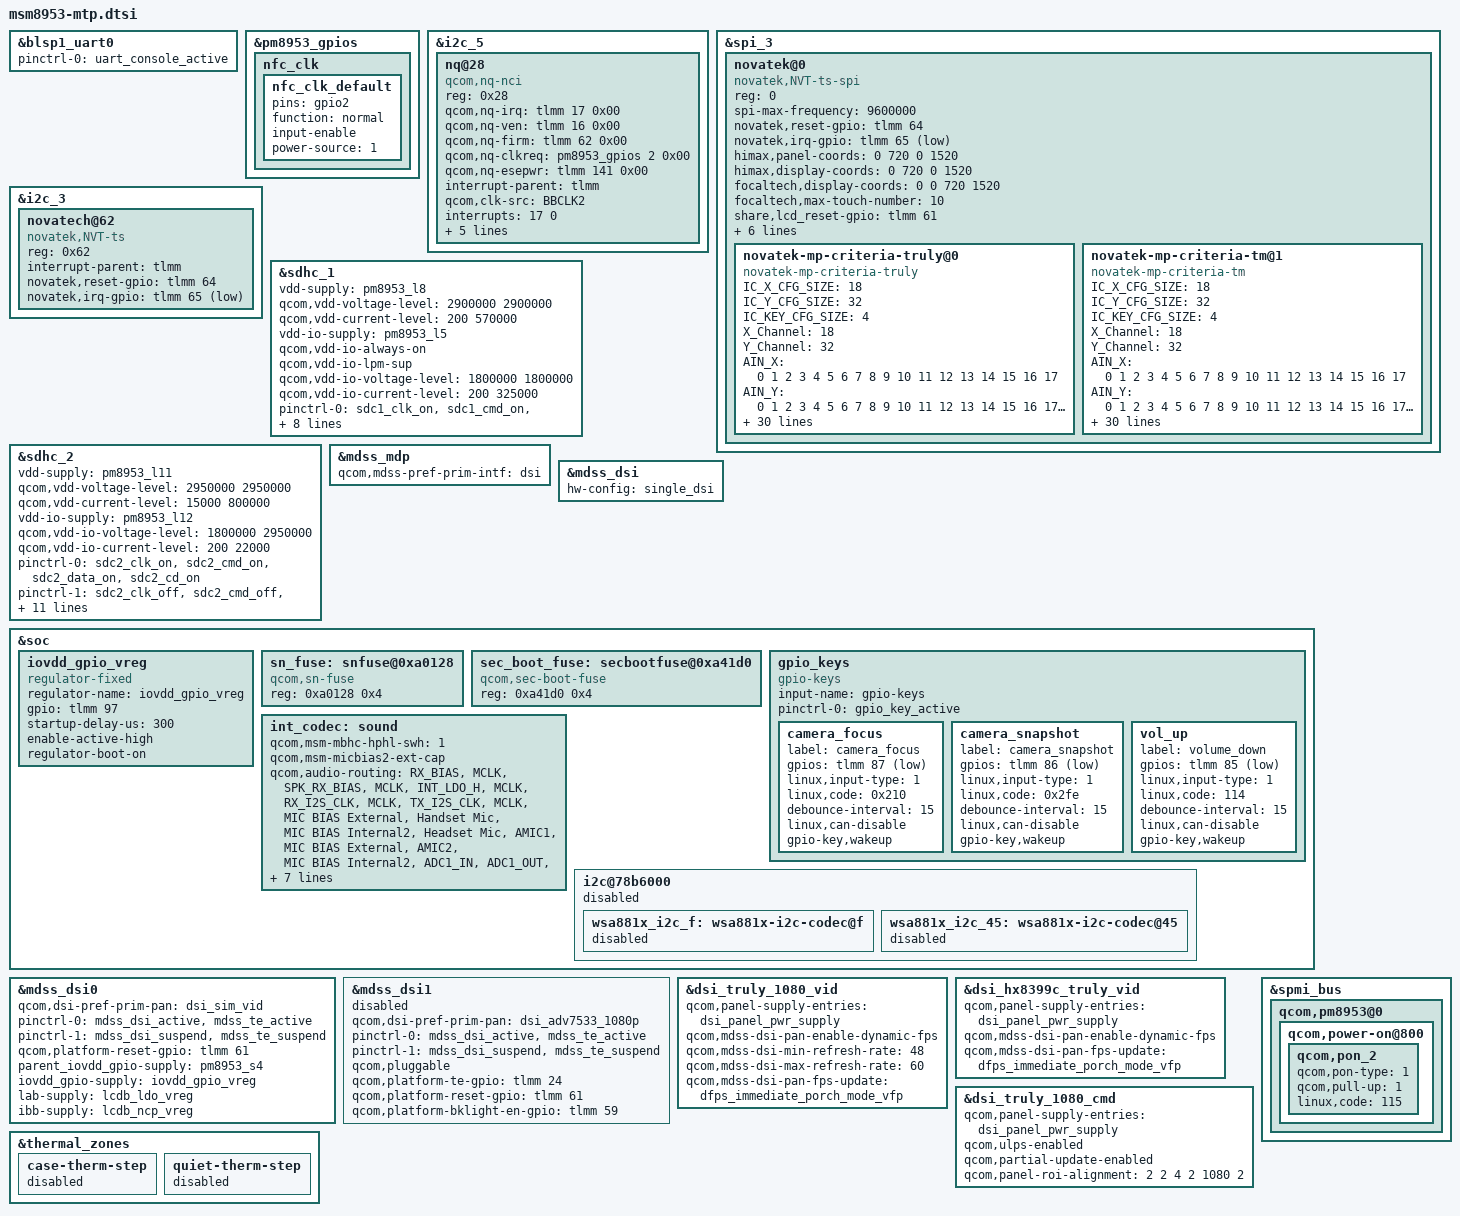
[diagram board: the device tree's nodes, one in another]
/*
 * Copyright (c) 2015-2018, The Linux Foundation. All rights reserved.
 *
 * This program is free software; you can redistribute it and/or modify
 * it under the terms of the GNU General Public License version 2 and
 * only version 2 as published by the Free Software Foundation.
 *
 * This program is distributed in the hope that it will be useful,
 * but WITHOUT ANY WARRANTY; without even the implied warranty of
 * MERCHANTABILITY or FITNESS FOR A PARTICULAR PURPOSE.  See the
 * GNU General Public License for more details.
 */

#include <dt-bindings/gpio/gpio.h>
#include <dt-bindings/clock/msm-clocks-8953.h>

//#include "msm8953-camera-sensor-mtp.dtsi"
#include "sdm450-camera-sensor-mtp-S88051AA1.dtsi"

&blsp1_uart0 {
	status = "ok";
	pinctrl-names = "default";
	pinctrl-0 = <&uart_console_active>;
};

&pm8953_gpios {
	nfc_clk {
		nfc_clk_default: nfc_clk_default {
			pins = "gpio2";
			function = "normal";
			input-enable;
			power-source = <1>;
		};
	};
};

&i2c_5 { /* BLSP2 QUP1 (NFC) */
	status = "ok";
	nq@28 {
		compatible = "qcom,nq-nci";
		reg = <0x28>;
		qcom,nq-irq = <&tlmm 17 0x00>;
		qcom,nq-ven = <&tlmm 16 0x00>;
		qcom,nq-firm = <&tlmm 62 0x00>;
		qcom,nq-clkreq = <&pm8953_gpios 2 0x00>;
		qcom,nq-esepwr = <&tlmm 141 0x00>;
		interrupt-parent = <&tlmm>;
		qcom,clk-src = "BBCLK2";
		interrupts = <17 0>;
		interrupt-names = "nfc_irq";
		pinctrl-names = "nfc_active", "nfc_suspend";
		pinctrl-0 = <&nfc_int_active &nfc_disable_active
						&nfc_clk_default>;
		pinctrl-1 = <&nfc_int_suspend &nfc_disable_suspend>;
		clocks = <&clock_gcc clk_bb_clk2_pin>;
		clock-names = "ref_clk";
	};
};

&spi_3 {
	status = "okay";
	novatek@0 {
		compatible = "novatek,NVT-ts-spi";
		reg = <0>; //Same as CS ID
		spi-max-frequency = <9600000>;	//4800000,9600000,15000000,19200000
		novatek,reset-gpio = <&tlmm 64 0x00>;
		novatek,irq-gpio = <&tlmm 65 0x2001>;
		himax,panel-coords = <0 720 0 1520>;
		himax,display-coords = <0 720 0 1520>;
		focaltech,display-coords = <0 0 720 1520>;
		focaltech,max-touch-number = <10>;
		share,lcd_reset-gpio = <&tlmm 61 0>;
		share,cs-gpio = <&tlmm 10 0>;
		lab-supply = <&lcdb_ldo_vreg>;
		ibb-supply = <&lcdb_ncp_vreg>;
		vdd-supply = <&iovdd_gpio_vreg>;
		//ctp-supply = <&pm8953_l5>;
		/* 672 */
		novatek,swrst-n8-addr = <0x01F01A>;
		novatek,mp-support-dt;
		novatek-mp-criteria-truly@0 {
			#address-cells = <1>;
			#size-cells = <0>;
			compatible = "novatek-mp-criteria-truly";
			status = "ok";
			/* MP Config */
			IC_X_CFG_SIZE = <18>;
			IC_Y_CFG_SIZE = <32>;
			IC_KEY_CFG_SIZE = <4>;
			X_Channel = <18>;
			Y_Channel = <32>;
			AIN_X = <0 1 2 3 4 5 6 7 8 9 10 11 12 13 14 15 16 17>;
			AIN_Y = <0 1 2 3 4 5 6 7 8 9 10 11 12 13 14 15 16 17 18 19
								20 21 22 23 24 25 26 27 28 29 30 31>;
			AIN_KEY = <0 1 2 0xFF>;

			/* MP Criteria */
			PS_Config_Lmt_Short_Rawdata_P = <
				14008 14008 14008 14008 14008 14008 14008 14008 14008 14008 14008 14008 14008 14008 14008 14008 14008 14008
				14008 14008 14008 14008 14008 14008 14008 14008 14008 14008 14008 14008 14008 14008 14008 14008 14008 14008
				14008 14008 14008 14008 14008 14008 14008 14008 14008 14008 14008 14008 14008 14008 14008 14008 14008 14008
				14008 14008 14008 14008 14008 14008 14008 14008 14008 14008 14008 14008 14008 14008 14008 14008 14008 14008
				14008 14008 14008 14008 14008 14008 14008 14008 14008 14008 14008 14008 14008 14008 14008 14008 14008 14008
				14008 14008 14008 14008 14008 14008 14008 14008 14008 14008 14008 14008 14008 14008 14008 14008 14008 14008
				14008 14008 14008 14008 14008 14008 14008 14008 14008 14008 14008 14008 14008 14008 14008 14008 14008 14008
				14008 14008 14008 14008 14008 14008 14008 14008 14008 14008 14008 14008 14008 14008 14008 14008 14008 14008
				14008 14008 14008 14008 14008 14008 14008 14008 14008 14008 14008 14008 14008 14008 14008 14008 14008 14008
				14008 14008 14008 14008 14008 14008 14008 14008 14008 14008 14008 14008 14008 14008 14008 14008 14008 14008
				14008 14008 14008 14008 14008 14008 14008 14008 14008 14008 14008 14008 14008 14008 14008 14008 14008 14008
				14008 14008 14008 14008 14008 14008 14008 14008 14008 14008 14008 14008 14008 14008 14008 14008 14008 14008
				14008 14008 14008 14008 14008 14008 14008 14008 14008 14008 14008 14008 14008 14008 14008 14008 14008 14008
				14008 14008 14008 14008 14008 14008 14008 14008 14008 14008 14008 14008 14008 14008 14008 14008 14008 14008
				14008 14008 14008 14008 14008 14008 14008 14008 14008 14008 14008 14008 14008 14008 14008 14008 14008 14008
				14008 14008 14008 14008 14008 14008 14008 14008 14008 14008 14008 14008 14008 14008 14008 14008 14008 14008
				14008 14008 14008 14008 14008 14008 14008 14008 14008 14008 14008 14008 14008 14008 14008 14008 14008 14008
				14008 14008 14008 14008 14008 14008 14008 14008 14008 14008 14008 14008 14008 14008 14008 14008 14008 14008
				14008 14008 14008 14008 14008 14008 14008 14008 14008 14008 14008 14008 14008 14008 14008 14008 14008 14008
				14008 14008 14008 14008 14008 14008 14008 14008 14008 14008 14008 14008 14008 14008 14008 14008 14008 14008
				14008 14008 14008 14008 14008 14008 14008 14008 14008 14008 14008 14008 14008 14008 14008 14008 14008 14008
				14008 14008 14008 14008 14008 14008 14008 14008 14008 14008 14008 14008 14008 14008 14008 14008 14008 14008
				14008 14008 14008 14008 14008 14008 14008 14008 14008 14008 14008 14008 14008 14008 14008 14008 14008 14008
				14008 14008 14008 14008 14008 14008 14008 14008 14008 14008 14008 14008 14008 14008 14008 14008 14008 14008
				14008 14008 14008 14008 14008 14008 14008 14008 14008 14008 14008 14008 14008 14008 14008 14008 14008 14008
				14008 14008 14008 14008 14008 14008 14008 14008 14008 14008 14008 14008 14008 14008 14008 14008 14008 14008
				14008 14008 14008 14008 14008 14008 14008 14008 14008 14008 14008 14008 14008 14008 14008 14008 14008 14008
				14008 14008 14008 14008 14008 14008 14008 14008 14008 14008 14008 14008 14008 14008 14008 14008 14008 14008
				14008 14008 14008 14008 14008 14008 14008 14008 14008 14008 14008 14008 14008 14008 14008 14008 14008 14008
				14008 14008 14008 14008 14008 14008 14008 14008 14008 14008 14008 14008 14008 14008 14008 14008 14008 14008
				14008 14008 14008 14008 14008 14008 14008 14008 14008 14008 14008 14008 14008 14008 14008 14008 14008 14008
				14008 14008 14008 14008 14008 14008 14008 14008 14008 14008 14008 14008 14008 14008 14008 14008 14008 14008
				>;

			PS_Config_Lmt_Short_Rawdata_N = <
				11376 11376 11376 11376 11376 11376 11376 11376 11376 11376 11376 11376 11376 11376 11376 11376 11376 11376
				11376 11376 11376 11376 11376 11376 11376 11376 11376 11376 11376 11376 11376 11376 11376 11376 11376 11376
				11376 11376 11376 11376 11376 11376 11376 11376 11376 11376 11376 11376 11376 11376 11376 11376 11376 11376
				11376 11376 11376 11376 11376 11376 11376 11376 11376 11376 11376 11376 11376 11376 11376 11376 11376 11376
				11376 11376 11376 11376 11376 11376 11376 11376 11376 11376 11376 11376 11376 11376 11376 11376 11376 11376
				11376 11376 11376 11376 11376 11376 11376 11376 11376 11376 11376 11376 11376 11376 11376 11376 11376 11376
				11376 11376 11376 11376 11376 11376 11376 11376 11376 11376 11376 11376 11376 11376 11376 11376 11376 11376
				11376 11376 11376 11376 11376 11376 11376 11376 11376 11376 11376 11376 11376 11376 11376 11376 11376 11376
				11376 11376 11376 11376 11376 11376 11376 11376 11376 11376 11376 11376 11376 11376 11376 11376 11376 11376
				11376 11376 11376 11376 11376 11376 11376 11376 11376 11376 11376 11376 11376 11376 11376 11376 11376 11376
				11376 11376 11376 11376 11376 11376 11376 11376 11376 11376 11376 11376 11376 11376 11376 11376 11376 11376
				11376 11376 11376 11376 11376 11376 11376 11376 11376 11376 11376 11376 11376 11376 11376 11376 11376 11376
				11376 11376 11376 11376 11376 11376 11376 11376 11376 11376 11376 11376 11376 11376 11376 11376 11376 11376
				11376 11376 11376 11376 11376 11376 11376 11376 11376 11376 11376 11376 11376 11376 11376 11376 11376 11376
				11376 11376 11376 11376 11376 11376 11376 11376 11376 11376 11376 11376 11376 11376 11376 11376 11376 11376
				11376 11376 11376 11376 11376 11376 11376 11376 11376 11376 11376 11376 11376 11376 11376 11376 11376 11376
				11376 11376 11376 11376 11376 11376 11376 11376 11376 11376 11376 11376 11376 11376 11376 11376 11376 11376
				11376 11376 11376 11376 11376 11376 11376 11376 11376 11376 11376 11376 11376 11376 11376 11376 11376 11376
				11376 11376 11376 11376 11376 11376 11376 11376 11376 11376 11376 11376 11376 11376 11376 11376 11376 11376
				11376 11376 11376 11376 11376 11376 11376 11376 11376 11376 11376 11376 11376 11376 11376 11376 11376 11376
				11376 11376 11376 11376 11376 11376 11376 11376 11376 11376 11376 11376 11376 11376 11376 11376 11376 11376
				11376 11376 11376 11376 11376 11376 11376 11376 11376 11376 11376 11376 11376 11376 11376 11376 11376 11376
				11376 11376 11376 11376 11376 11376 11376 11376 11376 11376 11376 11376 11376 11376 11376 11376 11376 11376
				11376 11376 11376 11376 11376 11376 11376 11376 11376 11376 11376 11376 11376 11376 11376 11376 11376 11376
				11376 11376 11376 11376 11376 11376 11376 11376 11376 11376 11376 11376 11376 11376 11376 11376 11376 11376
				11376 11376 11376 11376 11376 11376 11376 11376 11376 11376 11376 11376 11376 11376 11376 11376 11376 11376
				11376 11376 11376 11376 11376 11376 11376 11376 11376 11376 11376 11376 11376 11376 11376 11376 11376 11376
				11376 11376 11376 11376 11376 11376 11376 11376 11376 11376 11376 11376 11376 11376 11376 11376 11376 11376
				11376 11376 11376 11376 11376 11376 11376 11376 11376 11376 11376 11376 11376 11376 11376 11376 11376 11376
				11376 11376 11376 11376 11376 11376 11376 11376 11376 11376 11376 11376 11376 11376 11376 11376 11376 11376
				11376 11376 11376 11376 11376 11376 11376 11376 11376 11376 11376 11376 11376 11376 11376 11376 11376 11376
				11376 11376 11376 11376 11376 11376 11376 11376 11376 11376 11376 11376 11376 11376 11376 11376 11376 11376
				>;

			PS_Config_Lmt_Open_Rawdata_P = <
				2200	2004	1799	1603	1555	1710	65535	65535	65535	65535	65535	65535	1724	1562	1613	1811	2014	2209
				1752	1762	1753	1750	1751	1745	1745	1597	1583	1587	1600	1751	1751	1756	1759	1762	1769	1763
				1731	1735	1727	1724	1725	1718	1718	1723	1709	1710	1724	1722	1724	1728	1731	1734	1738	1740
				1718	1722	1713	1710	1711	1704	1704	1709	1695	1701	1715	1713	1714	1720	1722	1725	1730	1731
				1744	1748	1740	1736	1737	1731	1731	1735	1721	1730	1744	1742	1743	1748	1751	1754	1759	1761
				1741	1744	1735	1731	1733	1726	1726	1732	1717	1724	1739	1736	1738	1743	1746	1748	1753	1755
				1706	1709	1701	1696	1697	1691	1691	1696	1682	1689	1703	1701	1702	1707	1710	1713	1718	1721
				1705	1708	1699	1694	1696	1689	1689	1695	1680	1684	1698	1696	1697	1702	1705	1708	1713	1714
				1731	1734	1725	1721	1722	1716	1716	1721	1707	1714	1728	1726	1727	1732	1735	1738	1743	1745
				1728	1731	1722	1718	1720	1713	1713	1718	1703	1708	1723	1720	1722	1727	1730	1732	1738	1739
				1690	1692	1684	1679	1680	1674	1674	1679	1665	1670	1684	1682	1683	1688	1691	1694	1699	1701
				1686	1689	1680	1676	1678	1671	1670	1676	1661	1665	1680	1677	1678	1684	1686	1689	1695	1696
				1717	1719	1711	1706	1708	1702	1701	1706	1692	1699	1713	1710	1712	1717	1719	1723	1728	1731
				1712	1714	1705	1701	1703	1696	1696	1701	1686	1693	1708	1705	1707	1712	1714	1717	1724	1726
				1677	1678	1670	1666	1667	1661	1661	1665	1651	1656	1670	1667	1669	1674	1676	1679	1685	1688
				1672	1673	1665	1660	1662	1655	1655	1660	1645	1651	1665	1663	1664	1669	1671	1674	1681	1684
				1672	1672	1663	1660	1660	1654	1654	1658	1644	1649	1662	1660	1661	1666	1668	1672	1677	1681
				1665	1666	1657	1653	1654	1647	1647	1652	1637	1643	1657	1654	1655	1661	1662	1667	1672	1675
				1693	1693	1684	1680	1680	1674	1674	1678	1664	1671	1685	1683	1684	1689	1691	1696	1701	1705
				1686	1686	1677	1673	1674	1667	1667	1672	1657	1663	1678	1675	1677	1682	1683	1688	1694	1697
				1649	1648	1640	1636	1636	1630	1630	1634	1620	1626	1640	1638	1640	1645	1647	1652	1656	1661
				1644	1644	1635	1631	1632	1625	1625	1630	1615	1621	1636	1633	1634	1640	1641	1646	1652	1656
				1669	1670	1659	1655	1656	1649	1649	1653	1639	1647	1661	1658	1661	1666	1667	1673	1678	1683
				1665	1667	1655	1651	1652	1645	1645	1649	1635	1640	1655	1652	1654	1659	1661	1666	1674	1676
				1629	1629	1620	1615	1615	1609	1609	1613	1599	1605	1619	1617	1619	1624	1626	1631	1638	1641
				1627	1628	1619	1613	1614	1607	1607	1612	1597	1602	1617	1614	1616	1621	1623	1629	1636	1638
				1656	1655	1648	1641	1642	1635	1635	1639	1624	1628	1643	1641	1642	1648	1649	1657	1662	1666
				1652	1652	1644	1637	1638	1631	1631	1636	1620	1624	1640	1637	1639	1644	1646	1653	1659	1662
				1615	1614	1606	1599	1600	1594	1593	1598	1583	1587	1602	1600	1602	1607	1608	1616	1621	1625
				1618	1617	1609	1603	1604	1597	1596	1601	1586	1590	1605	1602	1605	1610	1612	1619	1624	1629
				1637	1635	1628	1620	1621	1614	1614	1618	1603	1608	1623	1621	1623	1628	1632	1638	1644	1649
				1297	1636	1627	1622	1620	1613	1612	1618	1602	1608	1625	1621	1624	1628	1632	1638	1645	1309
				>;

			PS_Config_Lmt_Open_Rawdata_N = <
				943	859	771	687	666	733	0	0	0	0	0	0	739	670	691	776	863	947
				751	755	751	750	750	748	748	684	679	680	686	751	750	753	754	755	758	755
				742	744	740	739	739	736	736	738	732	733	739	738	739	741	742	743	745	746
				736	738	734	733	733	730	730	732	726	729	735	734	735	737	738	739	741	742
				748	749	746	744	745	742	742	744	738	742	748	747	747	749	750	752	754	755
				746	747	744	742	743	740	740	742	736	739	745	744	745	747	748	749	751	752
				731	732	729	727	727	725	725	727	721	724	730	729	730	732	733	734	736	737
				731	732	728	726	727	724	724	726	720	722	728	727	727	730	731	732	734	735
				742	743	739	737	738	735	735	738	731	735	741	740	740	742	744	745	747	748
				741	742	738	736	737	734	734	736	730	732	738	737	738	740	741	742	745	745
				724	725	722	720	720	718	717	720	714	716	722	721	721	723	725	726	728	729
				723	724	720	718	719	716	716	718	712	714	720	719	719	722	722	724	726	727
				736	737	733	731	732	729	729	731	725	728	734	733	734	736	737	738	741	742
				734	734	731	729	730	727	727	729	723	726	732	731	731	734	735	736	739	740
				719	719	716	714	714	712	712	714	708	710	716	715	715	717	718	720	722	723
				716	717	713	712	712	709	709	711	705	708	714	713	713	715	716	717	720	722
				716	717	713	711	712	709	709	711	705	707	712	711	712	714	715	717	719	720
				713	714	710	708	709	706	706	708	702	704	710	709	709	712	712	714	717	718
				725	725	722	720	720	717	717	719	713	716	722	721	722	724	725	727	729	731
				722	723	719	717	717	714	714	717	710	713	719	718	719	721	721	724	726	727
				707	706	703	701	701	699	698	700	694	697	703	702	703	705	706	708	710	712
				705	705	701	699	699	696	696	698	692	695	701	700	700	703	703	706	708	710
				715	716	711	709	710	707	707	709	702	706	712	711	712	714	715	717	719	721
				714	714	709	708	708	705	705	707	701	703	709	708	709	711	712	714	717	718
				698	698	694	692	692	690	689	691	685	688	694	693	694	696	697	699	702	703
				697	698	694	691	692	689	689	691	684	687	693	692	692	695	696	698	701	702
				710	709	706	703	704	701	701	703	696	698	704	703	704	706	707	710	712	714
				708	708	705	701	702	699	699	701	694	696	703	702	702	705	705	708	711	712
				692	692	688	685	686	683	683	685	679	680	686	686	686	689	689	692	695	696
				694	693	690	687	687	684	684	686	680	681	688	687	688	690	691	694	696	698
				702	701	698	694	695	692	692	693	687	689	696	695	696	698	699	702	704	707
				556	701	697	695	694	691	691	693	686	689	696	695	696	698	699	702	705	561
				>;

			PS_Config_Lmt_FW_Rawdata_P = <
				824	827	832	825	838	825	65535	65535	65535	65535	65535	65535	856	841	851	843	856	855
				816	828	829	822	837	826	834	831	831	845	853	844	853	840	855	844	857	860
				818	825	839	824	832	827	834	830	834	843	855	844	853	840	853	841	855	863
				807	828	834	828	835	825	830	830	836	841	856	842	855	838	850	843	855	852
				813	823	836	828	832	829	832	831	830	843	852	843	854	839	852	841	856	860
				819	828	837	820	832	822	835	823	832	841	854	840	857	844	855	843	859	859
				815	819	825	826	836	822	834	825	832	841	855	840	854	842	855	834	840	863
				820	825	837	829	831	827	836	825	828	839	851	841	857	842	855	837	855	859
				820	827	840	827	829	828	837	830	836	841	852	843	856	841	854	840	858	862
				817	822	829	813	829	820	834	830	835	839	856	840	855	826	846	845	852	862
				816	823	836	834	831	825	833	829	833	841	861	840	851	839	861	847	856	863
				820	827	834	826	837	829	829	825	841	843	857	844	853	842	856	842	857	859
				819	828	837	831	832	813	822	830	831	846	856	832	846	846	859	839	853	862
				820	830	835	827	835	830	829	825	833	839	857	848	861	840	856	843	856	864
				812	829	834	822	839	828	830	829	829	843	855	839	855	843	857	846	858	864
				823	833	837	822	835	830	837	820	833	837	846	842	857	849	858	845	855	859
				825	828	832	828	835	830	836	826	833	845	853	841	858	844	854	841	857	860
				816	827	834	825	837	828	829	836	833	847	851	839	856	842	860	850	855	864
				835	832	835	825	836	832	835	827	832	846	859	842	850	844	856	844	853	875
				816	827	837	826	832	828	838	825	839	841	853	841	856	842	852	843	855	864
				821	829	840	830	830	826	835	828	836	845	854	847	852	840	857	847	854	861
				821	833	841	831	833	824	836	827	835	845	848	839	852	847	852	851	851	857
				822	824	832	824	835	837	838	823	843	839	850	843	856	843	850	842	853	858
				817	827	831	827	843	830	833	825	838	845	852	841	856	854	854	843	853	862
				817	823	833	829	838	832	826	827	838	848	854	842	852	850	855	842	857	863
				820	830	839	831	830	825	834	829	835	843	859	847	854	837	853	843	853	859
				818	827	832	826	832	833	846	827	836	840	853	857	856	845	855	841	859	859
				822	829	835	827	833	829	834	831	837	839	853	848	862	840	848	842	851	852
				820	825	834	826	838	829	835	824	836	845	852	843	854	840	857	845	853	858
				820	826	830	827	837	829	831	835	850	855	859	840	854	842	852	844	856	858
				820	828	835	831	831	822	837	832	836	848	854	844	854	841	851	843	851	860
				820	834	836	830	834	829	829	826	831	841	852	841	851	843	853	846	851	857
				>;

			PS_Config_Lmt_FW_Rawdata_N = <
				353	354	357	354	359	354	0	0	0	0	0	0	367	361	365	361	367	367
				350	355	355	352	359	354	358	356	356	362	365	362	365	360	367	362	367	369
				350	354	360	353	357	354	357	356	357	361	366	362	365	360	366	361	367	370
				346	355	358	355	358	353	356	356	358	360	367	361	366	359	364	361	366	365
				348	353	358	355	357	355	357	356	356	361	365	361	366	360	365	361	367	369
				351	355	359	351	357	352	358	353	357	360	366	360	367	362	366	361	368	368
				349	351	353	354	358	352	357	354	357	360	367	360	366	361	367	358	360	370
				351	354	359	355	356	355	358	354	355	360	365	361	367	361	367	359	366	368
				351	355	360	354	355	355	359	356	358	360	365	361	367	360	366	360	368	369
				350	352	355	348	355	352	358	356	358	360	367	360	366	354	362	362	365	370
				350	353	358	358	356	354	357	355	357	360	369	360	365	360	369	363	367	370
				351	354	358	354	359	355	355	353	361	361	367	362	365	361	367	361	367	368
				351	355	359	356	357	348	352	356	356	362	367	357	362	362	368	360	365	369
				351	356	358	354	358	356	355	354	357	360	367	363	369	360	367	361	367	370
				348	355	357	352	360	355	356	355	355	361	366	360	366	361	367	363	368	370
				353	357	359	352	358	356	359	351	357	359	363	361	367	364	368	362	366	368
				353	355	357	355	358	356	358	354	357	362	366	360	368	362	366	361	367	369
				350	354	357	354	359	355	355	358	357	363	365	359	367	361	369	364	367	370
				358	356	358	354	358	356	358	355	357	363	368	361	364	362	367	362	366	375
				350	355	359	354	356	355	359	353	360	360	365	360	367	361	365	361	366	370
				352	355	360	356	356	354	358	355	358	362	366	363	365	360	367	363	366	369
				352	357	360	356	357	353	358	354	358	362	363	360	365	363	365	365	365	367
				352	353	357	353	358	359	359	353	361	360	364	361	367	361	364	361	366	368
				350	354	356	355	361	356	357	354	359	362	365	360	367	366	366	361	365	369
				350	353	357	355	359	356	354	354	359	364	366	361	365	364	367	361	367	370
				351	356	360	356	356	353	357	355	358	361	368	363	366	359	366	361	366	368
				351	354	357	354	356	357	362	355	358	360	366	367	367	362	367	361	368	368
				352	355	358	354	357	355	358	356	359	360	366	363	369	360	363	361	365	365
				351	354	358	354	359	355	358	353	358	362	365	361	366	360	367	362	366	368
				352	354	356	354	359	355	356	358	364	367	368	360	366	361	365	362	367	368
				352	355	358	356	356	352	359	357	358	363	366	362	366	361	365	361	365	368
				351	357	358	356	357	355	355	354	356	360	365	360	365	361	366	362	365	367
				>;

			PS_Config_Lmt_FW_CC_P = <
				127	126	127	127	127	128	65535	65535	65535	65535	65535	65535	131	131	130	130	129	130
				130	129	129	129	130	130	130	129	130	134	133	135	134	134	133	134	133	134
				129	128	128	129	129	129	130	130	132	135	132	133	132	132	132	132	131	132
				130	129	129	129	130	130	130	131	132	136	134	134	134	134	133	133	132	133
				130	129	129	130	130	131	131	131	133	137	135	135	134	134	133	134	133	134
				130	129	129	130	130	131	131	131	133	138	136	136	135	135	134	134	133	134
				130	129	129	130	130	131	131	131	133	137	135	135	134	134	133	133	132	133
				130	129	129	130	130	131	131	131	133	137	135	135	134	134	133	133	133	134
				130	129	130	130	130	131	131	131	133	137	135	135	134	134	134	134	133	134
				130	129	130	130	130	131	131	131	133	138	136	136	135	135	134	134	134	135
				131	130	130	130	131	131	131	132	133	136	134	134	134	134	133	133	133	134
				131	130	130	130	131	131	131	131	133	137	135	135	134	134	133	133	133	134
				131	130	130	131	131	131	131	132	134	138	136	136	135	135	134	134	134	135
				131	130	130	130	131	131	131	132	134	138	136	136	135	135	134	135	134	135
				131	130	130	130	131	131	132	132	134	137	135	135	134	134	133	133	132	134
				131	129	130	130	131	131	131	132	133	137	135	135	134	134	133	133	133	134
				131	130	130	130	131	131	131	132	134	138	135	135	134	135	134	134	133	134
				131	129	129	130	130	130	131	131	133	138	136	135	134	135	134	134	133	134
				132	130	131	131	131	132	132	132	134	138	135	135	134	135	134	134	133	134
				132	130	130	131	131	131	132	132	134	137	135	135	134	134	133	133	133	134
				131	129	130	130	130	130	131	131	133	136	134	134	134	134	133	133	132	133
				131	129	129	129	130	130	130	131	133	136	134	134	133	134	133	133	133	134
				132	130	131	131	131	131	131	132	134	137	134	134	133	134	133	133	133	134
				132	131	131	131	131	131	132	132	134	136	134	134	133	134	133	133	133	134
				131	130	130	130	130	131	131	131	133	136	134	134	133	133	133	133	132	134
				131	129	129	129	130	130	131	131	133	136	134	134	133	134	133	133	133	134
				132	130	130	131	131	131	132	132	134	136	134	134	133	133	132	133	132	134
				132	130	130	130	131	131	131	132	133	136	134	134	133	133	132	132	132	133
				131	129	129	129	130	130	130	131	132	135	133	134	133	133	132	132	132	133
				130	128	128	128	129	129	129	130	131	134	132	132	131	131	130	130	130	132
				132	130	130	130	131	131	131	131	133	135	133	133	132	132	131	131	131	133
				125	130	129	129	130	130	130	131	133	135	132	132	131	131	130	131	131	125
				>;

			PS_Config_Lmt_FW_CC_N = <
				76	75	76	76	76	77	0	0	0	0	0	0	78	78	78	78	77	78
				78	77	77	78	78	78	78	77	78	81	80	81	80	81	80	80	80	80
				77	77	77	77	78	78	78	78	79	81	79	80	79	79	79	79	79	79
				78	77	77	78	78	78	78	78	79	82	81	81	80	80	80	80	79	80
				78	77	78	78	78	78	79	79	80	82	81	81	81	81	80	80	80	80
				78	77	77	78	78	78	78	79	80	83	81	81	81	81	80	80	80	81
				78	77	78	78	78	79	79	79	80	82	81	81	80	80	80	80	79	80
				78	78	78	78	78	78	79	79	80	82	81	81	80	81	80	80	80	80
				78	78	78	78	78	78	79	79	80	82	81	81	81	81	80	80	80	80
				78	78	78	78	78	78	78	79	80	83	81	81	81	81	80	81	80	81
				79	78	78	78	78	79	79	79	80	82	80	81	80	80	80	80	80	80
				78	78	78	78	78	78	79	79	80	82	81	81	80	80	80	80	80	80
				79	78	78	78	79	79	79	79	80	83	81	81	81	81	80	81	80	81
				79	78	78	78	78	79	79	79	80	83	82	82	81	81	81	81	80	81
				79	78	78	78	78	79	79	79	80	82	81	81	80	80	80	80	79	80
				78	78	78	78	78	78	79	79	80	82	81	81	80	81	80	80	80	80
				79	78	78	78	78	79	79	79	80	83	81	81	81	81	80	80	80	80
				78	78	78	78	78	78	78	79	80	83	81	81	81	81	80	80	80	81
				79	78	78	79	79	79	79	79	81	83	81	81	81	81	80	80	80	80
				79	78	78	78	79	79	79	79	80	82	81	81	80	81	80	80	80	80
				79	78	78	78	78	78	78	79	80	82	81	81	80	80	80	80	79	80
				78	78	78	78	78	78	78	79	80	82	81	81	80	80	80	80	80	80
				79	78	78	78	79	79	79	79	80	82	81	81	80	80	80	80	80	80
				79	78	78	78	79	79	79	79	80	82	81	80	80	80	80	80	80	80
				79	78	78	78	78	78	79	79	80	82	80	81	80	80	80	80	79	80
				79	78	78	78	78	78	78	79	80	82	81	80	80	80	80	80	80	80
				79	78	78	78	79	79	79	79	80	82	80	80	80	80	79	80	79	80
				79	78	78	78	78	79	79	79	80	82	80	80	80	80	79	79	79	80
				79	78	78	78	78	78	78	78	79	81	80	80	80	80	79	79	79	80
				78	77	77	77	77	77	77	78	79	80	79	79	79	79	78	78	78	79
				79	78	78	78	78	78	79	79	80	81	80	80	79	79	79	79	79	80
				75	78	78	78	78	78	78	78	80	81	79	79	79	79	78	79	79	75
				>;

			PS_Config_Lmt_FW_Diff_P = <
				50 50 50 50 50 50 65535 65535 65535 65535 65535 65535 50 50 50 50 50 50
				50 50 50 50 50 50    50    50    50    50    50    50 50 50 50 50 50 50
				50 50 50 50 50 50    50    50    50    50    50    50 50 50 50 50 50 50
				50 50 50 50 50 50    50    50    50    50    50    50 50 50 50 50 50 50
				50 50 50 50 50 50    50    50    50    50    50    50 50 50 50 50 50 50
				50 50 50 50 50 50    50    50    50    50    50    50 50 50 50 50 50 50
				50 50 50 50 50 50    50    50    50    50    50    50 50 50 50 50 50 50
				50 50 50 50 50 50    50    50    50    50    50    50 50 50 50 50 50 50
				50 50 50 50 50 50    50    50    50    50    50    50 50 50 50 50 50 50
				50 50 50 50 50 50    50    50    50    50    50    50 50 50 50 50 50 50
				50 50 50 50 50 50    50    50    50    50    50    50 50 50 50 50 50 50
				50 50 50 50 50 50    50    50    50    50    50    50 50 50 50 50 50 50
				50 50 50 50 50 50    50    50    50    50    50    50 50 50 50 50 50 50
				50 50 50 50 50 50    50    50    50    50    50    50 50 50 50 50 50 50
				50 50 50 50 50 50    50    50    50    50    50    50 50 50 50 50 50 50
				50 50 50 50 50 50    50    50    50    50    50    50 50 50 50 50 50 50
				50 50 50 50 50 50    50    50    50    50    50    50 50 50 50 50 50 50
				50 50 50 50 50 50    50    50    50    50    50    50 50 50 50 50 50 50
				50 50 50 50 50 50    50    50    50    50    50    50 50 50 50 50 50 50
				50 50 50 50 50 50    50    50    50    50    50    50 50 50 50 50 50 50
				50 50 50 50 50 50    50    50    50    50    50    50 50 50 50 50 50 50
				50 50 50 50 50 50    50    50    50    50    50    50 50 50 50 50 50 50
				50 50 50 50 50 50    50    50    50    50    50    50 50 50 50 50 50 50
				50 50 50 50 50 50    50    50    50    50    50    50 50 50 50 50 50 50
				50 50 50 50 50 50    50    50    50    50    50    50 50 50 50 50 50 50
				50 50 50 50 50 50    50    50    50    50    50    50 50 50 50 50 50 50
				50 50 50 50 50 50    50    50    50    50    50    50 50 50 50 50 50 50
				50 50 50 50 50 50    50    50    50    50    50    50 50 50 50 50 50 50
				50 50 50 50 50 50    50    50    50    50    50    50 50 50 50 50 50 50
				50 50 50 50 50 50    50    50    50    50    50    50 50 50 50 50 50 50
				50 50 50 50 50 50    50    50    50    50    50    50 50 50 50 50 50 50
				50 50 50 50 50 50    50    50    50    50    50    50 50 50 50 50 50 50
				>;

			PS_Config_Lmt_FW_Diff_N = <
				(-50) (-50) (-50) (-50) (-50) (-50) (-65535) (-65535) (-65535) (-65535) (-65535) (-65535) (-50) (-50) (-50) (-50) (-50) (-50)
				(-50) (-50) (-50) (-50) (-50) (-50)    (-50)    (-50)    (-50)    (-50)    (-50)    (-50) (-50) (-50) (-50) (-50) (-50) (-50)
				(-50) (-50) (-50) (-50) (-50) (-50)    (-50)    (-50)    (-50)    (-50)    (-50)    (-50) (-50) (-50) (-50) (-50) (-50) (-50)
				(-50) (-50) (-50) (-50) (-50) (-50)    (-50)    (-50)    (-50)    (-50)    (-50)    (-50) (-50) (-50) (-50) (-50) (-50) (-50)
				(-50) (-50) (-50) (-50) (-50) (-50)    (-50)    (-50)    (-50)    (-50)    (-50)    (-50) (-50) (-50) (-50) (-50) (-50) (-50)
				(-50) (-50) (-50) (-50) (-50) (-50)    (-50)    (-50)    (-50)    (-50)    (-50)    (-50) (-50) (-50) (-50) (-50) (-50) (-50)
				(-50) (-50) (-50) (-50) (-50) (-50)    (-50)    (-50)    (-50)    (-50)    (-50)    (-50) (-50) (-50) (-50) (-50) (-50) (-50)
				(-50) (-50) (-50) (-50) (-50) (-50)    (-50)    (-50)    (-50)    (-50)    (-50)    (-50) (-50) (-50) (-50) (-50) (-50) (-50)
				(-50) (-50) (-50) (-50) (-50) (-50)    (-50)    (-50)    (-50)    (-50)    (-50)    (-50) (-50) (-50) (-50) (-50) (-50) (-50)
				(-50) (-50) (-50) (-50) (-50) (-50)    (-50)    (-50)    (-50)    (-50)    (-50)    (-50) (-50) (-50) (-50) (-50) (-50) (-50)
				(-50) (-50) (-50) (-50) (-50) (-50)    (-50)    (-50)    (-50)    (-50)    (-50)    (-50) (-50) (-50) (-50) (-50) (-50) (-50)
				(-50) (-50) (-50) (-50) (-50) (-50)    (-50)    (-50)    (-50)    (-50)    (-50)    (-50) (-50) (-50) (-50) (-50) (-50) (-50)
				(-50) (-50) (-50) (-50) (-50) (-50)    (-50)    (-50)    (-50)    (-50)    (-50)    (-50) (-50) (-50) (-50) (-50) (-50) (-50)
				(-50) (-50) (-50) (-50) (-50) (-50)    (-50)    (-50)    (-50)    (-50)    (-50)    (-50) (-50) (-50) (-50) (-50) (-50) (-50)
				(-50) (-50) (-50) (-50) (-50) (-50)    (-50)    (-50)    (-50)    (-50)    (-50)    (-50) (-50) (-50) (-50) (-50) (-50) (-50)
				(-50) (-50) (-50) (-50) (-50) (-50)    (-50)    (-50)    (-50)    (-50)    (-50)    (-50) (-50) (-50) (-50) (-50) (-50) (-50)
				(-50) (-50) (-50) (-50) (-50) (-50)    (-50)    (-50)    (-50)    (-50)    (-50)    (-50) (-50) (-50) (-50) (-50) (-50) (-50)
				(-50) (-50) (-50) (-50) (-50) (-50)    (-50)    (-50)    (-50)    (-50)    (-50)    (-50) (-50) (-50) (-50) (-50) (-50) (-50)
				(-50) (-50) (-50) (-50) (-50) (-50)    (-50)    (-50)    (-50)    (-50)    (-50)    (-50) (-50) (-50) (-50) (-50) (-50) (-50)
				(-50) (-50) (-50) (-50) (-50) (-50)    (-50)    (-50)    (-50)    (-50)    (-50)    (-50) (-50) (-50) (-50) (-50) (-50) (-50)
				(-50) (-50) (-50) (-50) (-50) (-50)    (-50)    (-50)    (-50)    (-50)    (-50)    (-50) (-50) (-50) (-50) (-50) (-50) (-50)
				(-50) (-50) (-50) (-50) (-50) (-50)    (-50)    (-50)    (-50)    (-50)    (-50)    (-50) (-50) (-50) (-50) (-50) (-50) (-50)
				(-50) (-50) (-50) (-50) (-50) (-50)    (-50)    (-50)    (-50)    (-50)    (-50)    (-50) (-50) (-50) (-50) (-50) (-50) (-50)
				(-50) (-50) (-50) (-50) (-50) (-50)    (-50)    (-50)    (-50)    (-50)    (-50)    (-50) (-50) (-50) (-50) (-50) (-50) (-50)
				(-50) (-50) (-50) (-50) (-50) (-50)    (-50)    (-50)    (-50)    (-50)    (-50)    (-50) (-50) (-50) (-50) (-50) (-50) (-50)
				(-50) (-50) (-50) (-50) (-50) (-50)    (-50)    (-50)    (-50)    (-50)    (-50)    (-50) (-50) (-50) (-50) (-50) (-50) (-50)
				(-50) (-50) (-50) (-50) (-50) (-50)    (-50)    (-50)    (-50)    (-50)    (-50)    (-50) (-50) (-50) (-50) (-50) (-50) (-50)
				(-50) (-50) (-50) (-50) (-50) (-50)    (-50)    (-50)    (-50)    (-50)    (-50)    (-50) (-50) (-50) (-50) (-50) (-50) (-50)
				(-50) (-50) (-50) (-50) (-50) (-50)    (-50)    (-50)    (-50)    (-50)    (-50)    (-50) (-50) (-50) (-50) (-50) (-50) (-50)
				(-50) (-50) (-50) (-50) (-50) (-50)    (-50)    (-50)    (-50)    (-50)    (-50)    (-50) (-50) (-50) (-50) (-50) (-50) (-50)
				(-50) (-50) (-50) (-50) (-50) (-50)    (-50)    (-50)    (-50)    (-50)    (-50)    (-50) (-50) (-50) (-50) (-50) (-50) (-50)
				(-50) (-50) (-50) (-50) (-50) (-50)    (-50)    (-50)    (-50)    (-50)    (-50)    (-50) (-50) (-50) (-50) (-50) (-50) (-50)
				>;

			PS_Config_Diff_Test_Frame = <50>;

			PS_Config_Lmt_LPWG_Rawdata_P = <
				800 800 800 800 800 800 65535 65535 65535 65535 65535 65535 800 800 800 800 800 800
				800 800 800 800 800 800   800   800   800   800   800   800 800 800 800 800 800 800
				800 800 800 800 800 800   800   800   800   800   800   800 800 800 800 800 800 800
				800 800 800 800 800 800   800   800   800   800   800   800 800 800 800 800 800 800
				800 800 800 800 800 800   800   800   800   800   800   800 800 800 800 800 800 800
				800 800 800 800 800 800   800   800   800   800   800   800 800 800 800 800 800 800
				800 800 800 800 800 800   800   800   800   800   800   800 800 800 800 800 800 800
				800 800 800 800 800 800   800   800   800   800   800   800 800 800 800 800 800 800
				800 800 800 800 800 800   800   800   800   800   800   800 800 800 800 800 800 800
				800 800 800 800 800 800   800   800   800   800   800   800 800 800 800 800 800 800
				800 800 800 800 800 800   800   800   800   800   800   800 800 800 800 800 800 800
				800 800 800 800 800 800   800   800   800   800   800   800 800 800 800 800 800 800
				800 800 800 800 800 800   800   800   800   800   800   800 800 800 800 800 800 800
				800 800 800 800 800 800   800   800   800   800   800   800 800 800 800 800 800 800
				800 800 800 800 800 800   800   800   800   800   800   800 800 800 800 800 800 800
				800 800 800 800 800 800   800   800   800   800   800   800 800 800 800 800 800 800
				800 800 800 800 800 800   800   800   800   800   800   800 800 800 800 800 800 800
				800 800 800 800 800 800   800   800   800   800   800   800 800 800 800 800 800 800
				800 800 800 800 800 800   800   800   800   800   800   800 800 800 800 800 800 800
				800 800 800 800 800 800   800   800   800   800   800   800 800 800 800 800 800 800
				800 800 800 800 800 800   800   800   800   800   800   800 800 800 800 800 800 800
				800 800 800 800 800 800   800   800   800   800   800   800 800 800 800 800 800 800
				800 800 800 800 800 800   800   800   800   800   800   800 800 800 800 800 800 800
				800 800 800 800 800 800   800   800   800   800   800   800 800 800 800 800 800 800
				800 800 800 800 800 800   800   800   800   800   800   800 800 800 800 800 800 800
				800 800 800 800 800 800   800   800   800   800   800   800 800 800 800 800 800 800
				800 800 800 800 800 800   800   800   800   800   800   800 800 800 800 800 800 800
				800 800 800 800 800 800   800   800   800   800   800   800 800 800 800 800 800 800
				800 800 800 800 800 800   800   800   800   800   800   800 800 800 800 800 800 800
				800 800 800 800 800 800   800   800   800   800   800   800 800 800 800 800 800 800
				800 800 800 800 800 800   800   800   800   800   800   800 800 800 800 800 800 800
				800 800 800 800 800 800   800   800   800   800   800   800 800 800 800 800 800 800
				>;

			PS_Config_Lmt_LPWG_Rawdata_N = <
				400 400 400 400 400 400   0   0   0   0   0   0 400 400 400 400 400 400
				400 400 400 400 400 400 400 400 400 400 400 400 400 400 400 400 400 400
				400 400 400 400 400 400 400 400 400 400 400 400 400 400 400 400 400 400
				400 400 400 400 400 400 400 400 400 400 400 400 400 400 400 400 400 400
				400 400 400 400 400 400 400 400 400 400 400 400 400 400 400 400 400 400
				400 400 400 400 400 400 400 400 400 400 400 400 400 400 400 400 400 400
				400 400 400 400 400 400 400 400 400 400 400 400 400 400 400 400 400 400
				400 400 400 400 400 400 400 400 400 400 400 400 400 400 400 400 400 400
				400 400 400 400 400 400 400 400 400 400 400 400 400 400 400 400 400 400
				400 400 400 400 400 400 400 400 400 400 400 400 400 400 400 400 400 400
				400 400 400 400 400 400 400 400 400 400 400 400 400 400 400 400 400 400
				400 400 400 400 400 400 400 400 400 400 400 400 400 400 400 400 400 400
				400 400 400 400 400 400 400 400 400 400 400 400 400 400 400 400 400 400
				400 400 400 400 400 400 400 400 400 400 400 400 400 400 400 400 400 400
				400 400 400 400 400 400 400 400 400 400 400 400 400 400 400 400 400 400
				400 400 400 400 400 400 400 400 400 400 400 400 400 400 400 400 400 400
				400 400 400 400 400 400 400 400 400 400 400 400 400 400 400 400 400 400
				400 400 400 400 400 400 400 400 400 400 400 400 400 400 400 400 400 400
				400 400 400 400 400 400 400 400 400 400 400 400 400 400 400 400 400 400
				400 400 400 400 400 400 400 400 400 400 400 400 400 400 400 400 400 400
				400 400 400 400 400 400 400 400 400 400 400 400 400 400 400 400 400 400
				400 400 400 400 400 400 400 400 400 400 400 400 400 400 400 400 400 400
				400 400 400 400 400 400 400 400 400 400 400 400 400 400 400 400 400 400
				400 400 400 400 400 400 400 400 400 400 400 400 400 400 400 400 400 400
				400 400 400 400 400 400 400 400 400 400 400 400 400 400 400 400 400 400
				400 400 400 400 400 400 400 400 400 400 400 400 400 400 400 400 400 400
				400 400 400 400 400 400 400 400 400 400 400 400 400 400 400 400 400 400
				400 400 400 400 400 400 400 400 400 400 400 400 400 400 400 400 400 400
				400 400 400 400 400 400 400 400 400 400 400 400 400 400 400 400 400 400
				400 400 400 400 400 400 400 400 400 400 400 400 400 400 400 400 400 400
				400 400 400 400 400 400 400 400 400 400 400 400 400 400 400 400 400 400
				400 400 400 400 400 400 400 400 400 400 400 400 400 400 400 400 400 400
				>;

			PS_Config_Lmt_LPWG_Diff_P = <
				50 50 50 50 50 50 65535 65535 65535 65535 65535 65535 50 50 50 50 50 50
				50 50 50 50 50 50    50    50    50    50    50    50 50 50 50 50 50 50
				50 50 50 50 50 50    50    50    50    50    50    50 50 50 50 50 50 50
				50 50 50 50 50 50    50    50    50    50    50    50 50 50 50 50 50 50
				50 50 50 50 50 50    50    50    50    50    50    50 50 50 50 50 50 50
				50 50 50 50 50 50    50    50    50    50    50    50 50 50 50 50 50 50
				50 50 50 50 50 50    50    50    50    50    50    50 50 50 50 50 50 50
				50 50 50 50 50 50    50    50    50    50    50    50 50 50 50 50 50 50
				50 50 50 50 50 50    50    50    50    50    50    50 50 50 50 50 50 50
				50 50 50 50 50 50    50    50    50    50    50    50 50 50 50 50 50 50
				50 50 50 50 50 50    50    50    50    50    50    50 50 50 50 50 50 50
				50 50 50 50 50 50    50    50    50    50    50    50 50 50 50 50 50 50
				50 50 50 50 50 50    50    50    50    50    50    50 50 50 50 50 50 50
				50 50 50 50 50 50    50    50    50    50    50    50 50 50 50 50 50 50
				50 50 50 50 50 50    50    50    50    50    50    50 50 50 50 50 50 50
				50 50 50 50 50 50    50    50    50    50    50    50 50 50 50 50 50 50
				50 50 50 50 50 50    50    50    50    50    50    50 50 50 50 50 50 50
				50 50 50 50 50 50    50    50    50    50    50    50 50 50 50 50 50 50
				50 50 50 50 50 50    50    50    50    50    50    50 50 50 50 50 50 50
				50 50 50 50 50 50    50    50    50    50    50    50 50 50 50 50 50 50
				50 50 50 50 50 50    50    50    50    50    50    50 50 50 50 50 50 50
				50 50 50 50 50 50    50    50    50    50    50    50 50 50 50 50 50 50
				50 50 50 50 50 50    50    50    50    50    50    50 50 50 50 50 50 50
				50 50 50 50 50 50    50    50    50    50    50    50 50 50 50 50 50 50
				50 50 50 50 50 50    50    50    50    50    50    50 50 50 50 50 50 50
				50 50 50 50 50 50    50    50    50    50    50    50 50 50 50 50 50 50
				50 50 50 50 50 50    50    50    50    50    50    50 50 50 50 50 50 50
				50 50 50 50 50 50    50    50    50    50    50    50 50 50 50 50 50 50
				50 50 50 50 50 50    50    50    50    50    50    50 50 50 50 50 50 50
				50 50 50 50 50 50    50    50    50    50    50    50 50 50 50 50 50 50
				50 50 50 50 50 50    50    50    50    50    50    50 50 50 50 50 50 50
				50 50 50 50 50 50    50    50    50    50    50    50 50 50 50 50 50 50
				>;

			PS_Config_Lmt_LPWG_Diff_N = <
				(-50) (-50) (-50) (-50) (-50) (-50) (-65535) (-65535) (-65535) (-65535) (-65535) (-65535) (-50) (-50) (-50) (-50) (-50) (-50)
				(-50) (-50) (-50) (-50) (-50) (-50)    (-50)    (-50)    (-50)    (-50)    (-50)    (-50) (-50) (-50) (-50) (-50) (-50) (-50)
				(-50) (-50) (-50) (-50) (-50) (-50)    (-50)    (-50)    (-50)    (-50)    (-50)    (-50) (-50) (-50) (-50) (-50) (-50) (-50)
				(-50) (-50) (-50) (-50) (-50) (-50)    (-50)    (-50)    (-50)    (-50)    (-50)    (-50) (-50) (-50) (-50) (-50) (-50) (-50)
				(-50) (-50) (-50) (-50) (-50) (-50)    (-50)    (-50)    (-50)    (-50)    (-50)    (-50) (-50) (-50) (-50) (-50) (-50) (-50)
				(-50) (-50) (-50) (-50) (-50) (-50)    (-50)    (-50)    (-50)    (-50)    (-50)    (-50) (-50) (-50) (-50) (-50) (-50) (-50)
				(-50) (-50) (-50) (-50) (-50) (-50)    (-50)    (-50)    (-50)    (-50)    (-50)    (-50) (-50) (-50) (-50) (-50) (-50) (-50)
				(-50) (-50) (-50) (-50) (-50) (-50)    (-50)    (-50)    (-50)    (-50)    (-50)    (-50) (-50) (-50) (-50) (-50) (-50) (-50)
				(-50) (-50) (-50) (-50) (-50) (-50)    (-50)    (-50)    (-50)    (-50)    (-50)    (-50) (-50) (-50) (-50) (-50) (-50) (-50)
				(-50) (-50) (-50) (-50) (-50) (-50)    (-50)    (-50)    (-50)    (-50)    (-50)    (-50) (-50) (-50) (-50) (-50) (-50) (-50)
				(-50) (-50) (-50) (-50) (-50) (-50)    (-50)    (-50)    (-50)    (-50)    (-50)    (-50) (-50) (-50) (-50) (-50) (-50) (-50)
				(-50) (-50) (-50) (-50) (-50) (-50)    (-50)    (-50)    (-50)    (-50)    (-50)    (-50) (-50) (-50) (-50) (-50) (-50) (-50)
				(-50) (-50) (-50) (-50) (-50) (-50)    (-50)    (-50)    (-50)    (-50)    (-50)    (-50) (-50) (-50) (-50) (-50) (-50) (-50)
				(-50) (-50) (-50) (-50) (-50) (-50)    (-50)    (-50)    (-50)    (-50)    (-50)    (-50) (-50) (-50) (-50) (-50) (-50) (-50)
				(-50) (-50) (-50) (-50) (-50) (-50)    (-50)    (-50)    (-50)    (-50)    (-50)    (-50) (-50) (-50) (-50) (-50) (-50) (-50)
				(-50) (-50) (-50) (-50) (-50) (-50)    (-50)    (-50)    (-50)    (-50)    (-50)    (-50) (-50) (-50) (-50) (-50) (-50) (-50)
				(-50) (-50) (-50) (-50) (-50) (-50)    (-50)    (-50)    (-50)    (-50)    (-50)    (-50) (-50) (-50) (-50) (-50) (-50) (-50)
				(-50) (-50) (-50) (-50) (-50) (-50)    (-50)    (-50)    (-50)    (-50)    (-50)    (-50) (-50) (-50) (-50) (-50) (-50) (-50)
				(-50) (-50) (-50) (-50) (-50) (-50)    (-50)    (-50)    (-50)    (-50)    (-50)    (-50) (-50) (-50) (-50) (-50) (-50) (-50)
				(-50) (-50) (-50) (-50) (-50) (-50)    (-50)    (-50)    (-50)    (-50)    (-50)    (-50) (-50) (-50) (-50) (-50) (-50) (-50)
				(-50) (-50) (-50) (-50) (-50) (-50)    (-50)    (-50)    (-50)    (-50)    (-50)    (-50) (-50) (-50) (-50) (-50) (-50) (-50)
				(-50) (-50) (-50) (-50) (-50) (-50)    (-50)    (-50)    (-50)    (-50)    (-50)    (-50) (-50) (-50) (-50) (-50) (-50) (-50)
				(-50) (-50) (-50) (-50) (-50) (-50)    (-50)    (-50)    (-50)    (-50)    (-50)    (-50) (-50) (-50) (-50) (-50) (-50) (-50)
				(-50) (-50) (-50) (-50) (-50) (-50)    (-50)    (-50)    (-50)    (-50)    (-50)    (-50) (-50) (-50) (-50) (-50) (-50) (-50)
				(-50) (-50) (-50) (-50) (-50) (-50)    (-50)    (-50)    (-50)    (-50)    (-50)    (-50) (-50) (-50) (-50) (-50) (-50) (-50)
				(-50) (-50) (-50) (-50) (-50) (-50)    (-50)    (-50)    (-50)    (-50)    (-50)    (-50) (-50) (-50) (-50) (-50) (-50) (-50)
				(-50) (-50) (-50) (-50) (-50) (-50)    (-50)    (-50)    (-50)    (-50)    (-50)    (-50) (-50) (-50) (-50) (-50) (-50) (-50)
				(-50) (-50) (-50) (-50) (-50) (-50)    (-50)    (-50)    (-50)    (-50)    (-50)    (-50) (-50) (-50) (-50) (-50) (-50) (-50)
				(-50) (-50) (-50) (-50) (-50) (-50)    (-50)    (-50)    (-50)    (-50)    (-50)    (-50) (-50) (-50) (-50) (-50) (-50) (-50)
				(-50) (-50) (-50) (-50) (-50) (-50)    (-50)    (-50)    (-50)    (-50)    (-50)    (-50) (-50) (-50) (-50) (-50) (-50) (-50)
				(-50) (-50) (-50) (-50) (-50) (-50)    (-50)    (-50)    (-50)    (-50)    (-50)    (-50) (-50) (-50) (-50) (-50) (-50) (-50)
				(-50) (-50) (-50) (-50) (-50) (-50)    (-50)    (-50)    (-50)    (-50)    (-50)    (-50) (-50) (-50) (-50) (-50) (-50) (-50)
				>;
		};

		novatek-mp-criteria-tm@1 {
			#address-cells = <1>;
			#size-cells = <0>;
			compatible = "novatek-mp-criteria-tm";
			status = "ok";
			/* MP Config */
			IC_X_CFG_SIZE = <18>;
			IC_Y_CFG_SIZE = <32>;
			IC_KEY_CFG_SIZE = <4>;
			X_Channel = <18>;
			Y_Channel = <32>;
			AIN_X = <0 1 2 3 4 5 6 7 8 9 10 11 12 13 14 15 16 17>;
			AIN_Y = <0 1 2 3 4 5 6 7 8 9 10 11 12 13 14 15 16 17 18 19
								20 21 22 23 24 25 26 27 28 29 30 31>;
			AIN_KEY = <0 1 2 0xFF>;

			/* MP Criteria */
			PS_Config_Lmt_Short_Rawdata_P = <
				14008 14008 14008 14008 14008 14008 14008 14008 14008 14008 14008 14008 14008 14008 14008 14008 14008 14008
				14008 14008 14008 14008 14008 14008 14008 14008 14008 14008 14008 14008 14008 14008 14008 14008 14008 14008
				14008 14008 14008 14008 14008 14008 14008 14008 14008 14008 14008 14008 14008 14008 14008 14008 14008 14008
				14008 14008 14008 14008 14008 14008 14008 14008 14008 14008 14008 14008 14008 14008 14008 14008 14008 14008
				14008 14008 14008 14008 14008 14008 14008 14008 14008 14008 14008 14008 14008 14008 14008 14008 14008 14008
				14008 14008 14008 14008 14008 14008 14008 14008 14008 14008 14008 14008 14008 14008 14008 14008 14008 14008
				14008 14008 14008 14008 14008 14008 14008 14008 14008 14008 14008 14008 14008 14008 14008 14008 14008 14008
				14008 14008 14008 14008 14008 14008 14008 14008 14008 14008 14008 14008 14008 14008 14008 14008 14008 14008
				14008 14008 14008 14008 14008 14008 14008 14008 14008 14008 14008 14008 14008 14008 14008 14008 14008 14008
				14008 14008 14008 14008 14008 14008 14008 14008 14008 14008 14008 14008 14008 14008 14008 14008 14008 14008
				14008 14008 14008 14008 14008 14008 14008 14008 14008 14008 14008 14008 14008 14008 14008 14008 14008 14008
				14008 14008 14008 14008 14008 14008 14008 14008 14008 14008 14008 14008 14008 14008 14008 14008 14008 14008
				14008 14008 14008 14008 14008 14008 14008 14008 14008 14008 14008 14008 14008 14008 14008 14008 14008 14008
				14008 14008 14008 14008 14008 14008 14008 14008 14008 14008 14008 14008 14008 14008 14008 14008 14008 14008
				14008 14008 14008 14008 14008 14008 14008 14008 14008 14008 14008 14008 14008 14008 14008 14008 14008 14008
				14008 14008 14008 14008 14008 14008 14008 14008 14008 14008 14008 14008 14008 14008 14008 14008 14008 14008
				14008 14008 14008 14008 14008 14008 14008 14008 14008 14008 14008 14008 14008 14008 14008 14008 14008 14008
				14008 14008 14008 14008 14008 14008 14008 14008 14008 14008 14008 14008 14008 14008 14008 14008 14008 14008
				14008 14008 14008 14008 14008 14008 14008 14008 14008 14008 14008 14008 14008 14008 14008 14008 14008 14008
				14008 14008 14008 14008 14008 14008 14008 14008 14008 14008 14008 14008 14008 14008 14008 14008 14008 14008
				14008 14008 14008 14008 14008 14008 14008 14008 14008 14008 14008 14008 14008 14008 14008 14008 14008 14008
				14008 14008 14008 14008 14008 14008 14008 14008 14008 14008 14008 14008 14008 14008 14008 14008 14008 14008
				14008 14008 14008 14008 14008 14008 14008 14008 14008 14008 14008 14008 14008 14008 14008 14008 14008 14008
				14008 14008 14008 14008 14008 14008 14008 14008 14008 14008 14008 14008 14008 14008 14008 14008 14008 14008
				14008 14008 14008 14008 14008 14008 14008 14008 14008 14008 14008 14008 14008 14008 14008 14008 14008 14008
				14008 14008 14008 14008 14008 14008 14008 14008 14008 14008 14008 14008 14008 14008 14008 14008 14008 14008
				14008 14008 14008 14008 14008 14008 14008 14008 14008 14008 14008 14008 14008 14008 14008 14008 14008 14008
				14008 14008 14008 14008 14008 14008 14008 14008 14008 14008 14008 14008 14008 14008 14008 14008 14008 14008
				14008 14008 14008 14008 14008 14008 14008 14008 14008 14008 14008 14008 14008 14008 14008 14008 14008 14008
				14008 14008 14008 14008 14008 14008 14008 14008 14008 14008 14008 14008 14008 14008 14008 14008 14008 14008
				14008 14008 14008 14008 14008 14008 14008 14008 14008 14008 14008 14008 14008 14008 14008 14008 14008 14008
				14008 14008 14008 14008 14008 14008 14008 14008 14008 14008 14008 14008 14008 14008 14008 14008 14008 14008
				>;

			PS_Config_Lmt_Short_Rawdata_N = <
				11376 11376 11376 11376 11376 11376 11376 11376 11376 11376 11376 11376 11376 11376 11376 11376 11376 11376
				11376 11376 11376 11376 11376 11376 11376 11376 11376 11376 11376 11376 11376 11376 11376 11376 11376 11376
				11376 11376 11376 11376 11376 11376 11376 11376 11376 11376 11376 11376 11376 11376 11376 11376 11376 11376
				11376 11376 11376 11376 11376 11376 11376 11376 11376 11376 11376 11376 11376 11376 11376 11376 11376 11376
				11376 11376 11376 11376 11376 11376 11376 11376 11376 11376 11376 11376 11376 11376 11376 11376 11376 11376
				11376 11376 11376 11376 11376 11376 11376 11376 11376 11376 11376 11376 11376 11376 11376 11376 11376 11376
				11376 11376 11376 11376 11376 11376 11376 11376 11376 11376 11376 11376 11376 11376 11376 11376 11376 11376
				11376 11376 11376 11376 11376 11376 11376 11376 11376 11376 11376 11376 11376 11376 11376 11376 11376 11376
				11376 11376 11376 11376 11376 11376 11376 11376 11376 11376 11376 11376 11376 11376 11376 11376 11376 11376
				11376 11376 11376 11376 11376 11376 11376 11376 11376 11376 11376 11376 11376 11376 11376 11376 11376 11376
				11376 11376 11376 11376 11376 11376 11376 11376 11376 11376 11376 11376 11376 11376 11376 11376 11376 11376
				11376 11376 11376 11376 11376 11376 11376 11376 11376 11376 11376 11376 11376 11376 11376 11376 11376 11376
				11376 11376 11376 11376 11376 11376 11376 11376 11376 11376 11376 11376 11376 11376 11376 11376 11376 11376
				11376 11376 11376 11376 11376 11376 11376 11376 11376 11376 11376 11376 11376 11376 11376 11376 11376 11376
				11376 11376 11376 11376 11376 11376 11376 11376 11376 11376 11376 11376 11376 11376 11376 11376 11376 11376
				11376 11376 11376 11376 11376 11376 11376 11376 11376 11376 11376 11376 11376 11376 11376 11376 11376 11376
				11376 11376 11376 11376 11376 11376 11376 11376 11376 11376 11376 11376 11376 11376 11376 11376 11376 11376
				11376 11376 11376 11376 11376 11376 11376 11376 11376 11376 11376 11376 11376 11376 11376 11376 11376 11376
				11376 11376 11376 11376 11376 11376 11376 11376 11376 11376 11376 11376 11376 11376 11376 11376 11376 11376
				11376 11376 11376 11376 11376 11376 11376 11376 11376 11376 11376 11376 11376 11376 11376 11376 11376 11376
				11376 11376 11376 11376 11376 11376 11376 11376 11376 11376 11376 11376 11376 11376 11376 11376 11376 11376
				11376 11376 11376 11376 11376 11376 11376 11376 11376 11376 11376 11376 11376 11376 11376 11376 11376 11376
				11376 11376 11376 11376 11376 11376 11376 11376 11376 11376 11376 11376 11376 11376 11376 11376 11376 11376
				11376 11376 11376 11376 11376 11376 11376 11376 11376 11376 11376 11376 11376 11376 11376 11376 11376 11376
				11376 11376 11376 11376 11376 11376 11376 11376 11376 11376 11376 11376 11376 11376 11376 11376 11376 11376
				11376 11376 11376 11376 11376 11376 11376 11376 11376 11376 11376 11376 11376 11376 11376 11376 11376 11376
				11376 11376 11376 11376 11376 11376 11376 11376 11376 11376 11376 11376 11376 11376 11376 11376 11376 11376
				11376 11376 11376 11376 11376 11376 11376 11376 11376 11376 11376 11376 11376 11376 11376 11376 11376 11376
				11376 11376 11376 11376 11376 11376 11376 11376 11376 11376 11376 11376 11376 11376 11376 11376 11376 11376
				11376 11376 11376 11376 11376 11376 11376 11376 11376 11376 11376 11376 11376 11376 11376 11376 11376 11376
				11376 11376 11376 11376 11376 11376 11376 11376 11376 11376 11376 11376 11376 11376 11376 11376 11376 11376
				11376 11376 11376 11376 11376 11376 11376 11376 11376 11376 11376 11376 11376 11376 11376 11376 11376 11376
				>;

			PS_Config_Lmt_Open_Rawdata_P = <
				65535 3500 3535 3292 3183 3032 65535 65535 65535 65535 65535 65535 3048 3195 3308 3534 3502 65535
				 2240 2136 2155 2106 2122 2095  2114  2042  2102  2091  2039  2108 2094 2114 2102 2139 2123  2227
				 2241 2132 2150 2106 2123 2101  2147  2132  2186  2181  2137  2145 2106 2120 2106 2139 2123  2222
				 2198 2087 2105 2064 2079 2057  2104  1927  1983  2147  2101  2111 2069 2085 2070 2102 1925  2031
				 2223 2112 2129 2088 2103 2081  2130  2117  2172  2167  2120  2130 2086 2104 2090 2120 2106  2209
				 2234 2120 2137 2098 2113 2090  2139  2129  2182  2176  2129  2139 2095 2111 2097 2129 2116  2220
				 2202 2090 2105 2068 2081 1895  1945  2096  2147  2150  2105  2114 2071 2087 1910 1946 2094  2197
				 2206 2093 2106 2070 2081 2061  2107  2098  2148  2154  2109  2119 2076 2093 2080 2111 2100  2204
				 2252 2138 2148 2113 2123 2105  2150  2142  2192  2187  2141  2150 2106 2125 2114 2145 2133  2239
				 2240 2126 2135 1939 1953 2094  2138  2132  2181  2192  2145  2155 1943 1967 2117 2149 2136  2244
				 2224 2112 2119 2086 2095 2078  2121  2115  2162  2164  2119  2129 2085 2103 2092 2123 2110  2217
				 2216 2102 2112 2079 2088 2072  2114  2109  2156  2163  2116  2126 2085 2102 2090 2122 2110  2217
				 2260 1978 1993 2123 2132 2114  2158  2151  2200  2202  1985  2000 2121 2140 2129 2161 2149  2256
				 2265 2150 2161 2127 2136 2117  2162  2155  2205  2204  2158  2168 2124 2143 2134 2167 2155  2263
				 2227 2115 2125 2091 2102 2083  2127  2121  2169  2166  2122  2133 2089 2109 2098 2133 2121  2227
				 2071 2124 2133 2100 2110 2091  2135  2129  2177  2007  2128  2140 2096 2116 2106 2139 2127  2235
				 2234 2121 2132 2098 2109 2091  2135  2127  2175  2185  2138  2149 2106 2126 2116 2151 2139  2247
				 2238 2126 2134 2100 2111 2093  2137  2093  2142  2179  2132  2144 2100 2121 2111 2146 2102  2207
				 2270 2167 2164 2129 2140 2122  2168  2025  2077  2212  2163  2174 2129 2151 2142 2177 2042  2143
				 2280 2176 2175 2140 2151 2132  2178  2171  2222  2204  2157  2168 2123 2144 2134 2169 2170  2269
				 2240 2138 2137 2104 2115 1927  1974  2135  2184  2178  2130  2142 2097 2119 1938 1976 2146  2244
				 2242 2139 2141 2104 2117 2097  2143  2136  2186  2186  2138  2149 2105 2126 2114 2155 2154  2253
				 2267 2163 2175 2132 2141 2125  2169  2161  2212  2218  2171  2182 2135 2157 2151 2196 2185  2285
				 2275 2171 2184 1978 1981 2132  2178  2169  2220  2224  2175  2190 1969 1996 2166 2204 2191  2293
				 2245 2144 2156 2122 2122 2104  2150  2140  2191  2195  2146  2162 2115 2139 2139 2178 2161  2265
				 2254 2150 2163 2131 2130 2111  2157  2147  2199  2194  2145  2162 2114 2139 2137 2177 2160  2264
				 2281 2000 2017 2155 2158 2135  2183  2171  2223  2229  2004  2026 2148 2179 2172 2214 2195  2304
				 2283 2176 2190 2158 2170 2137  2186  2175  2226  2233  2184  2205 2152 2193 2177 2219 2200  2311
				 2256 2150 2162 2131 2144 2110  2159  2147  2198  2193  2146  2167 2114 2154 2138 2179 2159  2269
				 2129 2198 2210 2178 2191 2157  2206  2194  2246  2067  2196  2219 2164 2205 2188 2229 2210  2322
				 2315 2202 2212 2180 2192 2158  2211  2197  2249  2240  2192  2217 2159 2201 2184 2223 2206  2321
				 1968 2383 2396 2358 2371 2333  2397  2373  2453  2436  2363  2398 2330 2376 2356 2401 2383  1979
				>;

			PS_Config_Lmt_Open_Rawdata_N = <
				  0 1500 1515 1411 1364 1299    0    0    0    0    0    0 1306 1369 1418 1515 1501   0
				960  916  924  902  910  898  906  875  901  896  874  903  898  906  901  917  910 954
				960  914  921  903  910  900  920  914  937  935  916  919  903  909  903  917  910 952
				942  895  902  884  891  882  902  826  850  920  900  905  887  894  887  901  825 870
				953  905  912  895  901  892  913  907  931  929  909  913  894  902  896  909  902 947
				957  909  916  899  906  896  917  912  935  933  913  917  898  905  899  912  907 951
				944  896  902  886  892  812  834  898  920  921  902  906  887  895  819  834  897 941
				945  897  902  887  892  883  903  899  921  923  904  908  890  897  891  905  900 944
				965  916  921  906  910  902  922  918  939  937  918  922  903  911  906  919  914 960
				960  911  915  831  837  898  916  914  935  939  919  924  833  843  907  921  915 962
				953  905  908  894  898  890  909  906  927  927  908  912  893  901  897  910  904 950
				950  901  905  891  895  888  906  904  924  927  907  911  894  901  896  909  904 950
				968  848  854  910  914  906  925  922  943  944  851  857  909  917  912  926  921 967
				971  921  926  912  915  907  927  924  945  944  925  929  910  919  915  929  924 970
				955  907  911  896  901  893  911  909  930  928  910  914  895  904  899  914  909 954
				888  910  914  900  904  896  915  912  933  860  912  917  898  907  903  917  912 958
				957  909  914  899  904  896  915  912  932  936  916  921  902  911  907  922  917 963
				959  911  915  900  905  897  916  897  918  934  914  919  900  909  905  920  901 946
				973  929  927  912  917  909  929  868  890  948  927  932  912  922  918  933  875 918
				977  932  932  917  922  914  933  930  952  945  924  929  910  919  914  930  930 972
				960  916  916  902  906  826  846  915  936  933  913  918  899  908  831  847  920 962
				961  917  918  902  907  899  918  915  937  937  916  921  902  911  906  924  923 965
				972  927  932  914  918  911  930  926  948  951  930  935  915  924  922  941  936 979
				975  931  936  848  849  914  933  929  951  953  932  938  844  855  928  944  939 983
				962  919  924  909  910  902  921  917  939  941  920  927  906  917  917  933  926 971
				966  922  927  913  913  905  924  920  942  940  919  926  906  917  916  933  926 970
				977  857  864  923  925  915  935  931  953  955  859  868  921  934  931  949  941 987
				979  933  938  925  930  916  937  932  954  957  936  945  922  940  933  951  943 991
				967  921  926  913  919  904  925  920  942  940  920  929  906  923  916  934  925 973
				913  942  947  934  939  924  945  940  963  886  941  951  927  945  938  955  947 995
				992  944  948  934  939  925  947  941  964  960  940  950  925  943  936  953  945 995
				843 1021 1027 1010 1016 1000 1027 1017 1051 1044 1013 1028  999 1018 1010 1029 1021 848
				>;

			PS_Config_Lmt_FW_Rawdata_P = <
				65535 838 838 812 841 819 65535 65535 65535 65535 65535 65535 839 837 837 851 837 65535
				  831 836 854 830 846 841   826   834   833   848   830   853 854 830 832 837 835   860
				  839 839 836 827 852 848   834   842   836   841   842   832 852 836 840 840 846   843
				  838 841 842 833 831 824   844   829   844   828   854   839 845 839 861 835 847   847
				  842 824 851 844 833 835   850   829   845   832   847   829 839 839 840 853 846   850
				  839 822 848 836 848 838   851   842   836   846   855   844 852 837 852 833 847   844
				  830 835 837 839 841 841   833   828   834   842   848   836 849 835 845 831 827   834
				  833 834 842 838 830 847   831   838   847   841   831   827 842 841 832 839 832   853
				  824 831 844 821 848 842   848   835   849   836   860   836 839 837 850 831 854   833
				  829 842 845 828 842 830   843   839   843   832   831   826 849 843 835 837 837   835
				  834 849 820 829 852 804   849   812   849   851   846   830 847 834 850 837 847   835
				  828 824 857 831 844 856   836   837   840   841   857   857 854 837 854 842 848   833
				  841 846 837 833 829 833   829   835   830   829   851   838 844 837 841 842 839   838
				  831 828 840 832 836 825   841   838   843   839   860   826 844 832 849 843 850   850
				  832 833 851 841 838 840   831   843   847   846   855   824 845 832 841 831 856   854
				  847 838 820 826 849 840   848   831   837   847   854   846 845 836 854 844 847   833
				  820 828 853 841 831 843   828   848   827   834   852   830 840 833 861 843 853   846
				  832 842 847 831 847 840   846   838   833   847   859   842 849 842 858 838 837   845
				  831 835 825 835 827 828   831   838   840   830   854   830 844 824 856 837 851   849
				  827 848 832 834 836 835   837   845   839   834   847   830 836 837 857 833 858   842
				  836 838 846 841 832 840   840   834   844   838   851   828 839 829 841 845 836   852
				  835 851 842 838 843 839   848   830   841   844   856   845 858 843 852 848 842   841
				  824 831 846 843 852 836   839   838   832   854   854   855 855 853 856 835 863   847
				  833 825 837 826 838 836   835   839   842   835   848   839 846 843 847 833 850   847
				  838 845 830 833 846 840   838   832   844   849   858   836 848 847 860 839 858   825
				  831 845 826 830 839 823   842   825   838   831   848   836 839 826 862 839 847   862
				  818 842 838 823 844 837   851   828   837   831   836   834 852 835 851 829 850   832
				  838 844 835 827 845 830   848   836   846   837   865   851 864 846 848 828 856   838
				  820 849 818 825 855 834   844   834   844   841   860   847 862 837 848 834 855   836
				  840 839 843 825 840 852   833   846   852   842   845   830 846 847 851 831 857   838
				  825 856 834 848 843 840   832   843   844   831   853   838 845 833 847 823 839   852
				  842 832 845 836 839 828   847   827   854   838   833   837 846 836 842 820 850   842
				>;

			PS_Config_Lmt_FW_Rawdata_N = <
				  0 359 359 348 361 351   0   0   0   0   0   0 360 359 359 365 359   0
				356 358 366 356 363 361 354 358 357 363 356 365 366 356 357 359 358 368
				360 360 358 355 365 363 358 361 358 361 361 357 365 358 360 360 363 361
				359 360 361 357 356 353 362 355 362 355 366 360 362 360 369 358 363 363
				361 353 365 362 357 358 364 355 362 357 363 355 360 360 360 366 363 364
				360 352 363 358 364 359 365 361 358 363 367 362 365 359 365 357 363 362
				356 358 359 360 360 360 357 355 357 361 363 358 364 358 362 356 355 357
				357 357 361 359 356 363 356 359 363 361 356 355 361 361 357 360 356 366
				353 356 362 352 363 361 364 358 364 358 369 358 360 359 364 356 366 357
				355 361 362 355 361 356 361 360 361 357 356 354 364 361 358 359 359 358
				357 364 351 355 365 345 364 348 364 365 363 356 363 358 364 359 363 358
				355 353 367 356 362 367 358 359 360 361 367 367 366 359 366 361 363 357
				360 362 359 357 355 357 355 358 356 355 365 359 362 359 360 361 359 359
				356 355 360 357 358 354 361 359 361 359 369 354 362 356 364 361 364 364
				357 357 365 361 359 360 356 361 363 362 366 353 362 357 361 356 367 366
				363 359 352 354 364 360 363 356 359 363 366 363 362 358 366 362 363 357
				351 355 365 360 356 361 355 363 355 358 365 356 360 357 369 361 365 362
				357 361 363 356 363 360 363 359 357 363 368 361 364 361 368 359 359 362
				356 358 354 358 355 355 356 359 360 356 366 356 362 353 367 359 365 364
				355 363 357 358 358 358 359 362 359 357 363 356 358 359 367 357 368 361
				358 359 363 360 356 360 360 357 362 359 365 355 359 355 361 362 358 365
				358 365 361 359 361 359 364 356 360 362 367 362 368 361 365 363 361 360
				353 356 363 361 365 358 360 359 357 366 366 366 367 366 367 358 370 363
				357 354 359 354 359 358 358 360 361 358 364 360 363 361 363 357 364 363
				359 362 356 357 363 360 359 357 362 364 368 358 364 363 369 360 368 354
				356 362 354 356 360 353 361 353 359 356 363 358 359 354 369 360 363 369
				351 361 359 353 362 359 365 355 359 356 358 358 365 358 365 355 364 357
				359 362 358 354 362 356 363 358 363 359 371 365 370 363 364 355 367 359
				351 364 351 354 366 357 362 358 362 361 369 363 369 359 363 357 367 358
				360 360 361 354 360 365 357 363 365 361 362 356 363 363 365 356 367 359
				354 367 358 363 361 360 357 361 362 356 366 359 362 357 363 353 360 365
				361 356 362 358 360 355 363 354 366 359 357 359 363 358 361 352 364 361
				>;

			PS_Config_Lmt_FW_CC_P = <
				65535 138 165 169 169 165 65535 65535 65535 65535 65535 65535 167 172 169 164 138 65535
				  135 134 134 135 135 135   135   135   137   137   135   135 136 136 135 134 133   134
				  133 132 132 133 133 133   133   133   135   137   135   135 135 135 134 134 133   134
				  135 134 134 135 135 136   135   135   137   139   137   137 137 137 135 135 134   136
				  135 134 134 135 136 136   135   136   138   140   138   138 137 137 136 136 135   136
				  136 135 135 136 136 137   136   137   139   140   137   137 137 137 136 136 135   136
				  136 134 135 135 136 136   136   136   138   141   138   138 138 138 137 136 136   137
				  136 134 135 135 136 136   136   136   138   141   139   138 138 138 137 137 136   137
				  137 136 136 137 137 137   137   138   140   141   138   138 138 138 137 137 135   137
				  137 135 136 136 137 137   137   137   139   141   139   139 138 138 137 137 136   138
				  137 135 136 136 137 137   137   137   139   141   139   139 139 139 138 137 136   138
				  136 135 135 135 136 136   136   136   139   141   139   139 139 139 138 137 136   138
				  138 136 137 137 138 138   138   138   140   143   141   140 140 140 140 139 138   140
				  139 137 138 138 139 139   139   139   141   143   140   140 140 140 139 139 138   140
				  138 136 137 137 138 138   138   138   140   143   140   140 140 140 139 139 138   140
				  138 137 138 138 138 138   138   139   141   143   141   141 141 141 140 140 139   141
				  138 137 137 137 138 138   138   138   141   144   141   141 141 141 140 140 139   141
				  139 137 138 138 139 139   139   139   142   143   141   140 140 140 139 140 139   141
				  139 137 138 138 139 139   139   139   141   145   142   142 142 142 141 141 140   142
				  140 138 139 139 140 140   140   140   142   144   142   142 142 141 140 141 140   142
				  139 137 137 137 138 139   138   139   141   143   141   141 141 141 140 140 139   141
				  139 137 138 138 139 139   139   140   142   143   141   141 141 141 140 140 140   142
				  139 137 137 138 139 139   139   139   141   144   142   142 142 142 141 141 140   143
				  139 137 138 138 139 139   139   139   142   145   142   142 142 142 141 141 141   143
				  140 138 139 139 139 140   139   140   142   145   142   143 142 142 141 142 141   144
				  141 139 139 139 140 141   140   140   143   145   142   142 142 142 141 141 141   143
				  140 137 138 138 138 139   138   139   141   146   143   143 143 143 142 142 142   145
				  141 139 139 139 140 141   140   140   143   145   142   142 142 142 141 142 141   144
				  140 137 138 138 138 139   138   139   141   145   142   142 142 142 141 141 141   144
				  139 137 137 137 138 138   138   138   141   143   140   140 140 140 139 139 139   141
				  140 138 138 138 139 139   139   139   142   146   143   143 143 143 142 142 142   145
				  132 138 138 138 138 139   138   139   142   145   141   141 141 141 140 141 141   133
				>;

			PS_Config_Lmt_FW_CC_N = <
				 0 80 80 80 80 80  0  0  0  0  0  0 80 80 80 80 80  0
				80 80 80 80 80 80 80 80 80 80 80 80 80 80 80 80 80 80
				80 80 80 80 80 80 80 80 80 80 80 80 80 80 80 80 80 80
				80 80 80 80 80 80 80 80 80 80 80 80 80 80 80 80 80 80
				80 80 80 80 80 80 80 80 80 80 80 80 80 80 80 80 80 80
				80 80 80 80 80 80 80 80 80 80 80 80 80 80 80 80 80 80
				80 80 80 80 80 80 80 80 80 80 80 80 80 80 80 80 80 80
				80 80 80 80 80 80 80 80 80 80 80 80 80 80 80 80 80 80
				80 80 80 80 80 80 80 80 80 80 80 80 80 80 80 80 80 80
				80 80 80 80 80 80 80 80 80 80 80 80 80 80 80 80 80 80
				80 80 80 80 80 80 80 80 80 80 80 80 80 80 80 80 80 80
				80 80 80 80 80 80 80 80 80 80 80 80 80 80 80 80 80 80
				80 80 80 80 80 80 80 80 80 80 80 80 80 80 80 80 80 80
				80 80 80 80 80 80 80 80 80 80 80 80 80 80 80 80 80 80
				80 80 80 80 80 80 80 80 80 80 80 80 80 80 80 80 80 80
				80 80 80 80 80 80 80 80 80 80 80 80 80 80 80 80 80 80
				80 80 80 80 80 80 80 80 80 80 80 80 80 80 80 80 80 80
				80 80 80 80 80 80 80 80 80 80 80 80 80 80 80 80 80 80
				80 80 80 80 80 80 80 80 80 80 80 80 80 80 80 80 80 80
				80 80 80 80 80 80 80 80 80 80 80 80 80 80 80 80 80 80
				80 80 80 80 80 80 80 80 80 80 80 80 80 80 80 80 80 80
				80 80 80 80 80 80 80 80 80 80 80 80 80 80 80 80 80 80
				80 80 80 80 80 80 80 80 80 80 80 80 80 80 80 80 80 80
				80 80 80 80 80 80 80 80 80 80 80 80 80 80 80 80 80 80
				80 80 80 80 80 80 80 80 80 80 80 80 80 80 80 80 80 80
				80 80 80 80 80 80 80 80 80 80 80 80 80 80 80 80 80 80
				80 80 80 80 80 80 80 80 80 80 80 80 80 80 80 80 80 80
				80 80 80 80 80 80 80 80 80 80 80 80 80 80 80 80 80 80
				80 80 80 80 80 80 80 80 80 80 80 80 80 80 80 80 80 80
				80 80 80 80 80 80 80 80 80 80 80 80 80 80 80 80 80 80
				80 80 80 80 80 80 80 80 80 80 80 80 80 80 80 80 80 80
				80 80 80 80 80 80 80 80 80 80 80 80 80 80 80 80 80 80
				>;

			PS_Config_Lmt_FW_Diff_P = <
				65535 35 35 35 35 35 65535 65535 65535 65535 65535 65535 35 35 35 35 35 65535
				   35 35 35 35 35 35    35    35    35    35    35    35 35 35 35 35 35    35
				   35 35 35 35 35 35    35    35    35    35    35    35 35 35 35 35 35    35
				   35 35 35 35 35 35    35    35    35    35    35    35 35 35 35 35 35    35
				   35 35 35 35 35 35    35    35    35    35    35    35 35 35 35 35 35    35
				   35 35 35 35 35 35    35    35    35    35    35    35 35 35 35 35 35    35
				   35 35 35 35 35 35    35    35    35    35    35    35 35 35 35 35 35    35
				   35 35 35 35 35 35    35    35    35    35    35    35 35 35 35 35 35    35
				   35 35 35 35 35 35    35    35    35    35    35    35 35 35 35 35 35    35
				   35 35 35 35 35 35    35    35    35    35    35    35 35 35 35 35 35    35
				   35 35 35 35 35 35    35    35    35    35    35    35 35 35 35 35 35    35
				   35 35 35 35 35 35    35    35    35    35    35    35 35 35 35 35 35    35
				   35 35 35 35 35 35    35    35    35    35    35    35 35 35 35 35 35    35
				   35 35 35 35 35 35    35    35    35    35    35    35 35 35 35 35 35    35
				   35 35 35 35 35 35    35    35    35    35    35    35 35 35 35 35 35    35
				   35 35 35 35 35 35    35    35    35    35    35    35 35 35 35 35 35    35
				   35 35 35 35 35 35    35    35    35    35    35    35 35 35 35 35 35    35
				   35 35 35 35 35 35    35    35    35    35    35    35 35 35 35 35 35    35
				   35 35 35 35 35 35    35    35    35    35    35    35 35 35 35 35 35    35
				   35 35 35 35 35 35    35    35    35    35    35    35 35 35 35 35 35    35
				   35 35 35 35 35 35    35    35    35    35    35    35 35 35 35 35 35    35
				   35 35 35 35 35 35    35    35    35    35    35    35 35 35 35 35 35    35
				   35 35 35 35 35 35    35    35    35    35    35    35 35 35 35 35 35    35
				   35 35 35 35 35 35    35    35    35    35    35    35 35 35 35 35 35    35
				   35 35 35 35 35 35    35    35    35    35    35    35 35 35 35 35 35    35
				   35 35 35 35 35 35    35    35    35    35    35    35 35 35 35 35 35    35
				   35 35 35 35 35 35    35    35    35    35    35    35 35 35 35 35 35    35
				   35 35 35 35 35 35    35    35    35    35    35    35 35 35 35 35 35    35
				   35 35 35 35 35 35    35    35    35    35    35    35 35 35 35 35 35    35
				   35 35 35 35 35 35    35    35    35    35    35    35 35 35 35 35 35    35
				   35 35 35 35 35 35    35    35    35    35    35    35 35 35 35 35 35    35
				   35 35 35 35 35 35    35    35    35    35    35    35 35 35 35 35 35    35
				>;

			PS_Config_Lmt_FW_Diff_N = <
				(-65535) (-35) (-35) (-35) (-35) (-35) (-65535) (-65535) (-65535) (-65535) (-65535) (-65535) (-35) (-35) (-35) (-35) (-35) (-65535)
				   (-35) (-35) (-35) (-35) (-35) (-35)    (-35)    (-35)    (-35)    (-35)    (-35)    (-35) (-35) (-35) (-35) (-35) (-35)    (-35)
				   (-35) (-35) (-35) (-35) (-35) (-35)    (-35)    (-35)    (-35)    (-35)    (-35)    (-35) (-35) (-35) (-35) (-35) (-35)    (-35)
				   (-35) (-35) (-35) (-35) (-35) (-35)    (-35)    (-35)    (-35)    (-35)    (-35)    (-35) (-35) (-35) (-35) (-35) (-35)    (-35)
				   (-35) (-35) (-35) (-35) (-35) (-35)    (-35)    (-35)    (-35)    (-35)    (-35)    (-35) (-35) (-35) (-35) (-35) (-35)    (-35)
				   (-35) (-35) (-35) (-35) (-35) (-35)    (-35)    (-35)    (-35)    (-35)    (-35)    (-35) (-35) (-35) (-35) (-35) (-35)    (-35)
				   (-35) (-35) (-35) (-35) (-35) (-35)    (-35)    (-35)    (-35)    (-35)    (-35)    (-35) (-35) (-35) (-35) (-35) (-35)    (-35)
				   (-35) (-35) (-35) (-35) (-35) (-35)    (-35)    (-35)    (-35)    (-35)    (-35)    (-35) (-35) (-35) (-35) (-35) (-35)    (-35)
				   (-35) (-35) (-35) (-35) (-35) (-35)    (-35)    (-35)    (-35)    (-35)    (-35)    (-35) (-35) (-35) (-35) (-35) (-35)    (-35)
				   (-35) (-35) (-35) (-35) (-35) (-35)    (-35)    (-35)    (-35)    (-35)    (-35)    (-35) (-35) (-35) (-35) (-35) (-35)    (-35)
				   (-35) (-35) (-35) (-35) (-35) (-35)    (-35)    (-35)    (-35)    (-35)    (-35)    (-35) (-35) (-35) (-35) (-35) (-35)    (-35)
				   (-35) (-35) (-35) (-35) (-35) (-35)    (-35)    (-35)    (-35)    (-35)    (-35)    (-35) (-35) (-35) (-35) (-35) (-35)    (-35)
				   (-35) (-35) (-35) (-35) (-35) (-35)    (-35)    (-35)    (-35)    (-35)    (-35)    (-35) (-35) (-35) (-35) (-35) (-35)    (-35)
				   (-35) (-35) (-35) (-35) (-35) (-35)    (-35)    (-35)    (-35)    (-35)    (-35)    (-35) (-35) (-35) (-35) (-35) (-35)    (-35)
				   (-35) (-35) (-35) (-35) (-35) (-35)    (-35)    (-35)    (-35)    (-35)    (-35)    (-35) (-35) (-35) (-35) (-35) (-35)    (-35)
				   (-35) (-35) (-35) (-35) (-35) (-35)    (-35)    (-35)    (-35)    (-35)    (-35)    (-35) (-35) (-35) (-35) (-35) (-35)    (-35)
				   (-35) (-35) (-35) (-35) (-35) (-35)    (-35)    (-35)    (-35)    (-35)    (-35)    (-35) (-35) (-35) (-35) (-35) (-35)    (-35)
				   (-35) (-35) (-35) (-35) (-35) (-35)    (-35)    (-35)    (-35)    (-35)    (-35)    (-35) (-35) (-35) (-35) (-35) (-35)    (-35)
				   (-35) (-35) (-35) (-35) (-35) (-35)    (-35)    (-35)    (-35)    (-35)    (-35)    (-35) (-35) (-35) (-35) (-35) (-35)    (-35)
				   (-35) (-35) (-35) (-35) (-35) (-35)    (-35)    (-35)    (-35)    (-35)    (-35)    (-35) (-35) (-35) (-35) (-35) (-35)    (-35)
				   (-35) (-35) (-35) (-35) (-35) (-35)    (-35)    (-35)    (-35)    (-35)    (-35)    (-35) (-35) (-35) (-35) (-35) (-35)    (-35)
				   (-35) (-35) (-35) (-35) (-35) (-35)    (-35)    (-35)    (-35)    (-35)    (-35)    (-35) (-35) (-35) (-35) (-35) (-35)    (-35)
				   (-35) (-35) (-35) (-35) (-35) (-35)    (-35)    (-35)    (-35)    (-35)    (-35)    (-35) (-35) (-35) (-35) (-35) (-35)    (-35)
				   (-35) (-35) (-35) (-35) (-35) (-35)    (-35)    (-35)    (-35)    (-35)    (-35)    (-35) (-35) (-35) (-35) (-35) (-35)    (-35)
				   (-35) (-35) (-35) (-35) (-35) (-35)    (-35)    (-35)    (-35)    (-35)    (-35)    (-35) (-35) (-35) (-35) (-35) (-35)    (-35)
				   (-35) (-35) (-35) (-35) (-35) (-35)    (-35)    (-35)    (-35)    (-35)    (-35)    (-35) (-35) (-35) (-35) (-35) (-35)    (-35)
				   (-35) (-35) (-35) (-35) (-35) (-35)    (-35)    (-35)    (-35)    (-35)    (-35)    (-35) (-35) (-35) (-35) (-35) (-35)    (-35)
				   (-35) (-35) (-35) (-35) (-35) (-35)    (-35)    (-35)    (-35)    (-35)    (-35)    (-35) (-35) (-35) (-35) (-35) (-35)    (-35)
				   (-35) (-35) (-35) (-35) (-35) (-35)    (-35)    (-35)    (-35)    (-35)    (-35)    (-35) (-35) (-35) (-35) (-35) (-35)    (-35)
				   (-35) (-35) (-35) (-35) (-35) (-35)    (-35)    (-35)    (-35)    (-35)    (-35)    (-35) (-35) (-35) (-35) (-35) (-35)    (-35)
				   (-35) (-35) (-35) (-35) (-35) (-35)    (-35)    (-35)    (-35)    (-35)    (-35)    (-35) (-35) (-35) (-35) (-35) (-35)    (-35)
				   (-35) (-35) (-35) (-35) (-35) (-35)    (-35)    (-35)    (-35)    (-35)    (-35)    (-35) (-35) (-35) (-35) (-35) (-35)    (-35)
				>;

			PS_Config_Diff_Test_Frame = <50>;

			PS_Config_Lmt_LPWG_Rawdata_P = <
				65535 800 800 800 800 800 65535 65535 65535 65535 65535 65535 800 800 800 800 800 65535
				  800 800 800 800 800 800   800   800   800   800   800   800 800 800 800 800 800   800
				  800 800 800 800 800 800   800   800   800   800   800   800 800 800 800 800 800   800
				  800 800 800 800 800 800   800   800   800   800   800   800 800 800 800 800 800   800
				  800 800 800 800 800 800   800   800   800   800   800   800 800 800 800 800 800   800
				  800 800 800 800 800 800   800   800   800   800   800   800 800 800 800 800 800   800
				  800 800 800 800 800 800   800   800   800   800   800   800 800 800 800 800 800   800
				  800 800 800 800 800 800   800   800   800   800   800   800 800 800 800 800 800   800
				  800 800 800 800 800 800   800   800   800   800   800   800 800 800 800 800 800   800
				  800 800 800 800 800 800   800   800   800   800   800   800 800 800 800 800 800   800
				  800 800 800 800 800 800   800   800   800   800   800   800 800 800 800 800 800   800
				  800 800 800 800 800 800   800   800   800   800   800   800 800 800 800 800 800   800
				  800 800 800 800 800 800   800   800   800   800   800   800 800 800 800 800 800   800
				  800 800 800 800 800 800   800   800   800   800   800   800 800 800 800 800 800   800
				  800 800 800 800 800 800   800   800   800   800   800   800 800 800 800 800 800   800
				  800 800 800 800 800 800   800   800   800   800   800   800 800 800 800 800 800   800
				  800 800 800 800 800 800   800   800   800   800   800   800 800 800 800 800 800   800
				  800 800 800 800 800 800   800   800   800   800   800   800 800 800 800 800 800   800
				  800 800 800 800 800 800   800   800   800   800   800   800 800 800 800 800 800   800
				  800 800 800 800 800 800   800   800   800   800   800   800 800 800 800 800 800   800
				  800 800 800 800 800 800   800   800   800   800   800   800 800 800 800 800 800   800
				  800 800 800 800 800 800   800   800   800   800   800   800 800 800 800 800 800   800
				  800 800 800 800 800 800   800   800   800   800   800   800 800 800 800 800 800   800
				  800 800 800 800 800 800   800   800   800   800   800   800 800 800 800 800 800   800
				  800 800 800 800 800 800   800   800   800   800   800   800 800 800 800 800 800   800
				  800 800 800 800 800 800   800   800   800   800   800   800 800 800 800 800 800   800
				  800 800 800 800 800 800   800   800   800   800   800   800 800 800 800 800 800   800
				  800 800 800 800 800 800   800   800   800   800   800   800 800 800 800 800 800   800
				  800 800 800 800 800 800   800   800   800   800   800   800 800 800 800 800 800   800
				  800 800 800 800 800 800   800   800   800   800   800   800 800 800 800 800 800   800
				  800 800 800 800 800 800   800   800   800   800   800   800 800 800 800 800 800   800
				  800 800 800 800 800 800   800   800   800   800   800   800 800 800 800 800 800   800
				>;

			PS_Config_Lmt_LPWG_Rawdata_N = <
				  0 400 400 400 400 400   0   0   0   0   0   0 400 400 400 400 400   0
				400 400 400 400 400 400 400 400 400 400 400 400 400 400 400 400 400 400
				400 400 400 400 400 400 400 400 400 400 400 400 400 400 400 400 400 400
				400 400 400 400 400 400 400 400 400 400 400 400 400 400 400 400 400 400
				400 400 400 400 400 400 400 400 400 400 400 400 400 400 400 400 400 400
				400 400 400 400 400 400 400 400 400 400 400 400 400 400 400 400 400 400
				400 400 400 400 400 400 400 400 400 400 400 400 400 400 400 400 400 400
				400 400 400 400 400 400 400 400 400 400 400 400 400 400 400 400 400 400
				400 400 400 400 400 400 400 400 400 400 400 400 400 400 400 400 400 400
				400 400 400 400 400 400 400 400 400 400 400 400 400 400 400 400 400 400
				400 400 400 400 400 400 400 400 400 400 400 400 400 400 400 400 400 400
				400 400 400 400 400 400 400 400 400 400 400 400 400 400 400 400 400 400
				400 400 400 400 400 400 400 400 400 400 400 400 400 400 400 400 400 400
				400 400 400 400 400 400 400 400 400 400 400 400 400 400 400 400 400 400
				400 400 400 400 400 400 400 400 400 400 400 400 400 400 400 400 400 400
				400 400 400 400 400 400 400 400 400 400 400 400 400 400 400 400 400 400
				400 400 400 400 400 400 400 400 400 400 400 400 400 400 400 400 400 400
				400 400 400 400 400 400 400 400 400 400 400 400 400 400 400 400 400 400
				400 400 400 400 400 400 400 400 400 400 400 400 400 400 400 400 400 400
				400 400 400 400 400 400 400 400 400 400 400 400 400 400 400 400 400 400
				400 400 400 400 400 400 400 400 400 400 400 400 400 400 400 400 400 400
				400 400 400 400 400 400 400 400 400 400 400 400 400 400 400 400 400 400
				400 400 400 400 400 400 400 400 400 400 400 400 400 400 400 400 400 400
				400 400 400 400 400 400 400 400 400 400 400 400 400 400 400 400 400 400
				400 400 400 400 400 400 400 400 400 400 400 400 400 400 400 400 400 400
				400 400 400 400 400 400 400 400 400 400 400 400 400 400 400 400 400 400
				400 400 400 400 400 400 400 400 400 400 400 400 400 400 400 400 400 400
				400 400 400 400 400 400 400 400 400 400 400 400 400 400 400 400 400 400
				400 400 400 400 400 400 400 400 400 400 400 400 400 400 400 400 400 400
				400 400 400 400 400 400 400 400 400 400 400 400 400 400 400 400 400 400
				400 400 400 400 400 400 400 400 400 400 400 400 400 400 400 400 400 400
				400 400 400 400 400 400 400 400 400 400 400 400 400 400 400 400 400 400
				>;

			PS_Config_Lmt_LPWG_Diff_P = <
				65535 35 35 35 35 35 65535 65535 65535 65535 65535 65535 35 35 35 35 35 65535
				   35 35 35 35 35 35    35    35    35    35    35    35 35 35 35 35 35    35
				   35 35 35 35 35 35    35    35    35    35    35    35 35 35 35 35 35    35
				   35 35 35 35 35 35    35    35    35    35    35    35 35 35 35 35 35    35
				   35 35 35 35 35 35    35    35    35    35    35    35 35 35 35 35 35    35
				   35 35 35 35 35 35    35    35    35    35    35    35 35 35 35 35 35    35
				   35 35 35 35 35 35    35    35    35    35    35    35 35 35 35 35 35    35
				   35 35 35 35 35 35    35    35    35    35    35    35 35 35 35 35 35    35
				   35 35 35 35 35 35    35    35    35    35    35    35 35 35 35 35 35    35
				   35 35 35 35 35 35    35    35    35    35    35    35 35 35 35 35 35    35
				   35 35 35 35 35 35    35    35    35    35    35    35 35 35 35 35 35    35
				   35 35 35 35 35 35    35    35    35    35    35    35 35 35 35 35 35    35
				   35 35 35 35 35 35    35    35    35    35    35    35 35 35 35 35 35    35
				   35 35 35 35 35 35    35    35    35    35    35    35 35 35 35 35 35    35
				   35 35 35 35 35 35    35    35    35    35    35    35 35 35 35 35 35    35
				   35 35 35 35 35 35    35    35    35    35    35    35 35 35 35 35 35    35
				   35 35 35 35 35 35    35    35    35    35    35    35 35 35 35 35 35    35
				   35 35 35 35 35 35    35    35    35    35    35    35 35 35 35 35 35    35
				   35 35 35 35 35 35    35    35    35    35    35    35 35 35 35 35 35    35
				   35 35 35 35 35 35    35    35    35    35    35    35 35 35 35 35 35    35
				   35 35 35 35 35 35    35    35    35    35    35    35 35 35 35 35 35    35
				   35 35 35 35 35 35    35    35    35    35    35    35 35 35 35 35 35    35
				   35 35 35 35 35 35    35    35    35    35    35    35 35 35 35 35 35    35
				   35 35 35 35 35 35    35    35    35    35    35    35 35 35 35 35 35    35
				   35 35 35 35 35 35    35    35    35    35    35    35 35 35 35 35 35    35
				   35 35 35 35 35 35    35    35    35    35    35    35 35 35 35 35 35    35
				   35 35 35 35 35 35    35    35    35    35    35    35 35 35 35 35 35    35
				   35 35 35 35 35 35    35    35    35    35    35    35 35 35 35 35 35    35
				   35 35 35 35 35 35    35    35    35    35    35    35 35 35 35 35 35    35
				   35 35 35 35 35 35    35    35    35    35    35    35 35 35 35 35 35    35
				   35 35 35 35 35 35    35    35    35    35    35    35 35 35 35 35 35    35
				   35 35 35 35 35 35    35    35    35    35    35    35 35 35 35 35 35    35
				>;

			PS_Config_Lmt_LPWG_Diff_N = <
				(-65535) (-35) (-35) (-35) (-35) (-35) (-65535) (-65535) (-65535) (-65535) (-65535) (-65535) (-35) (-35) (-35) (-35) (-35) (-65535)
				   (-35) (-35) (-35) (-35) (-35) (-35)    (-35)    (-35)    (-35)    (-35)    (-35)    (-35) (-35) (-35) (-35) (-35) (-35)    (-35)
				   (-35) (-35) (-35) (-35) (-35) (-35)    (-35)    (-35)    (-35)    (-35)    (-35)    (-35) (-35) (-35) (-35) (-35) (-35)    (-35)
				   (-35) (-35) (-35) (-35) (-35) (-35)    (-35)    (-35)    (-35)    (-35)    (-35)    (-35) (-35) (-35) (-35) (-35) (-35)    (-35)
				   (-35) (-35) (-35) (-35) (-35) (-35)    (-35)    (-35)    (-35)    (-35)    (-35)    (-35) (-35) (-35) (-35) (-35) (-35)    (-35)
				   (-35) (-35) (-35) (-35) (-35) (-35)    (-35)    (-35)    (-35)    (-35)    (-35)    (-35) (-35) (-35) (-35) (-35) (-35)    (-35)
				   (-35) (-35) (-35) (-35) (-35) (-35)    (-35)    (-35)    (-35)    (-35)    (-35)    (-35) (-35) (-35) (-35) (-35) (-35)    (-35)
				   (-35) (-35) (-35) (-35) (-35) (-35)    (-35)    (-35)    (-35)    (-35)    (-35)    (-35) (-35) (-35) (-35) (-35) (-35)    (-35)
				   (-35) (-35) (-35) (-35) (-35) (-35)    (-35)    (-35)    (-35)    (-35)    (-35)    (-35) (-35) (-35) (-35) (-35) (-35)    (-35)
				   (-35) (-35) (-35) (-35) (-35) (-35)    (-35)    (-35)    (-35)    (-35)    (-35)    (-35) (-35) (-35) (-35) (-35) (-35)    (-35)
				   (-35) (-35) (-35) (-35) (-35) (-35)    (-35)    (-35)    (-35)    (-35)    (-35)    (-35) (-35) (-35) (-35) (-35) (-35)    (-35)
				   (-35) (-35) (-35) (-35) (-35) (-35)    (-35)    (-35)    (-35)    (-35)    (-35)    (-35) (-35) (-35) (-35) (-35) (-35)    (-35)
				   (-35) (-35) (-35) (-35) (-35) (-35)    (-35)    (-35)    (-35)    (-35)    (-35)    (-35) (-35) (-35) (-35) (-35) (-35)    (-35)
				   (-35) (-35) (-35) (-35) (-35) (-35)    (-35)    (-35)    (-35)    (-35)    (-35)    (-35) (-35) (-35) (-35) (-35) (-35)    (-35)
				   (-35) (-35) (-35) (-35) (-35) (-35)    (-35)    (-35)    (-35)    (-35)    (-35)    (-35) (-35) (-35) (-35) (-35) (-35)    (-35)
				   (-35) (-35) (-35) (-35) (-35) (-35)    (-35)    (-35)    (-35)    (-35)    (-35)    (-35) (-35) (-35) (-35) (-35) (-35)    (-35)
				   (-35) (-35) (-35) (-35) (-35) (-35)    (-35)    (-35)    (-35)    (-35)    (-35)    (-35) (-35) (-35) (-35) (-35) (-35)    (-35)
				   (-35) (-35) (-35) (-35) (-35) (-35)    (-35)    (-35)    (-35)    (-35)    (-35)    (-35) (-35) (-35) (-35) (-35) (-35)    (-35)
				   (-35) (-35) (-35) (-35) (-35) (-35)    (-35)    (-35)    (-35)    (-35)    (-35)    (-35) (-35) (-35) (-35) (-35) (-35)    (-35)
				   (-35) (-35) (-35) (-35) (-35) (-35)    (-35)    (-35)    (-35)    (-35)    (-35)    (-35) (-35) (-35) (-35) (-35) (-35)    (-35)
				   (-35) (-35) (-35) (-35) (-35) (-35)    (-35)    (-35)    (-35)    (-35)    (-35)    (-35) (-35) (-35) (-35) (-35) (-35)    (-35)
				   (-35) (-35) (-35) (-35) (-35) (-35)    (-35)    (-35)    (-35)    (-35)    (-35)    (-35) (-35) (-35) (-35) (-35) (-35)    (-35)
				   (-35) (-35) (-35) (-35) (-35) (-35)    (-35)    (-35)    (-35)    (-35)    (-35)    (-35) (-35) (-35) (-35) (-35) (-35)    (-35)
				   (-35) (-35) (-35) (-35) (-35) (-35)    (-35)    (-35)    (-35)    (-35)    (-35)    (-35) (-35) (-35) (-35) (-35) (-35)    (-35)
				   (-35) (-35) (-35) (-35) (-35) (-35)    (-35)    (-35)    (-35)    (-35)    (-35)    (-35) (-35) (-35) (-35) (-35) (-35)    (-35)
				   (-35) (-35) (-35) (-35) (-35) (-35)    (-35)    (-35)    (-35)    (-35)    (-35)    (-35) (-35) (-35) (-35) (-35) (-35)    (-35)
				   (-35) (-35) (-35) (-35) (-35) (-35)    (-35)    (-35)    (-35)    (-35)    (-35)    (-35) (-35) (-35) (-35) (-35) (-35)    (-35)
				   (-35) (-35) (-35) (-35) (-35) (-35)    (-35)    (-35)    (-35)    (-35)    (-35)    (-35) (-35) (-35) (-35) (-35) (-35)    (-35)
				   (-35) (-35) (-35) (-35) (-35) (-35)    (-35)    (-35)    (-35)    (-35)    (-35)    (-35) (-35) (-35) (-35) (-35) (-35)    (-35)
				   (-35) (-35) (-35) (-35) (-35) (-35)    (-35)    (-35)    (-35)    (-35)    (-35)    (-35) (-35) (-35) (-35) (-35) (-35)    (-35)
				   (-35) (-35) (-35) (-35) (-35) (-35)    (-35)    (-35)    (-35)    (-35)    (-35)    (-35) (-35) (-35) (-35) (-35) (-35)    (-35)
				   (-35) (-35) (-35) (-35) (-35) (-35)    (-35)    (-35)    (-35)    (-35)    (-35)    (-35) (-35) (-35) (-35) (-35) (-35)    (-35)
				>;
		};

	};
};
&i2c_3 {
	status = "okay";
		novatech@62 {
				compatible = "novatek,NVT-ts";
				reg = <0x62>;
				interrupt-parent = <&tlmm>;
				status = "ok";
				novatek,reset-gpio = <&tlmm 64 0x00>;
				novatek,irq-gpio = <&tlmm 65 0x2001>;
			};
	};
&sdhc_1 {
	/* device core power supply */
	vdd-supply = <&pm8953_l8>;
	qcom,vdd-voltage-level = <2900000 2900000>;
	qcom,vdd-current-level = <200 570000>;

	/* device communication power supply */
	vdd-io-supply = <&pm8953_l5>;
	qcom,vdd-io-always-on;
	qcom,vdd-io-lpm-sup;
	qcom,vdd-io-voltage-level = <1800000 1800000>;
	qcom,vdd-io-current-level = <200 325000>;

	pinctrl-names = "active", "sleep";
	pinctrl-0 = <&sdc1_clk_on &sdc1_cmd_on &sdc1_data_on  &sdc1_rclk_on>;
	pinctrl-1 = <&sdc1_clk_off &sdc1_cmd_off &sdc1_data_off &sdc1_rclk_off>;

	qcom,clk-rates = <400000 20000000 25000000 50000000 100000000 192000000
								384000000>;
	qcom,nonremovable;
	qcom,bus-speed-mode = "HS400_1p8v", "HS200_1p8v", "DDR_1p8v";

	status = "ok";
};

&sdhc_2 {
	/* device core power supply */
	vdd-supply = <&pm8953_l11>;
	qcom,vdd-voltage-level = <2950000 2950000>;
	qcom,vdd-current-level = <15000 800000>;

	/* device communication power supply */
	vdd-io-supply = <&pm8953_l12>;
	qcom,vdd-io-voltage-level = <1800000 2950000>;
	qcom,vdd-io-current-level = <200 22000>;

	pinctrl-names = "active", "sleep";
	pinctrl-0 = <&sdc2_clk_on &sdc2_cmd_on &sdc2_data_on &sdc2_cd_on>;
	pinctrl-1 = <&sdc2_clk_off &sdc2_cmd_off &sdc2_data_off>;

	#address-cells = <0>;
	interrupt-parent = <&sdhc_2>;
	interrupts = <0 1 2>;
	#interrupt-cells = <1>;
	interrupt-map-mask = <0xffffffff>;
	interrupt-map = <0 &intc 0 125 0
		1 &intc 0 221 0
		2 &tlmm 133 0>;
	interrupt-names = "hc_irq", "pwr_irq", "status_irq";
	cd-gpios = <&tlmm 133 0x0>;

	qcom,clk-rates = <400000 20000000 25000000 50000000 100000000
								200000000>;
	qcom,bus-speed-mode = "SDR12", "SDR25", "SDR50", "DDR50", "SDR104";

	status = "ok";
};

#include "msm8953-mdss-panels.dtsi"

&mdss_mdp {
	qcom,mdss-pref-prim-intf = "dsi";
};

&mdss_dsi {
	hw-config = "single_dsi";
};

&soc {
 	iovdd_gpio_vreg: iovdd_gpio_vreg {
	compatible = "regulator-fixed";
	regulator-name="iovdd_gpio_vreg";
 	gpio = <&tlmm 97 0>; /* iovdd - ldo6 */
 	startup-delay-us = <300>;
 	enable-active-high;
	regulator-boot-on;
	status = "ok";
 };
};

&mdss_dsi0 {
	qcom,dsi-pref-prim-pan = <&dsi_sim_vid>;
	pinctrl-names = "mdss_default", "mdss_sleep";
	pinctrl-0 = <&mdss_dsi_active &mdss_te_active>;
	pinctrl-1 = <&mdss_dsi_suspend &mdss_te_suspend>;

	//qcom,platform-te-gpio = <&tlmm 24 0>;
		qcom,platform-reset-gpio = <&tlmm 61 0>;
	//qcom,platform-bklight-en-gpio = <&tlmm 59 0>;
	
 	parent_iovdd_gpio-supply = <&pm8953_s4>;
 	iovdd_gpio-supply = <&iovdd_gpio_vreg>;
	lab-supply = <&lcdb_ldo_vreg>;
	ibb-supply = <&lcdb_ncp_vreg>;

};

&mdss_dsi1 {
	status = "disabled";
	qcom,dsi-pref-prim-pan = <&dsi_adv7533_1080p>;
	pinctrl-names = "mdss_default", "mdss_sleep";
	pinctrl-0 = <&mdss_dsi_active &mdss_te_active>;
	pinctrl-1 = <&mdss_dsi_suspend &mdss_te_suspend>;

	qcom,pluggable;
	qcom,platform-te-gpio = <&tlmm 24 0>;
	qcom,platform-reset-gpio = <&tlmm 61 0>;
	qcom,platform-bklight-en-gpio = <&tlmm 59 0>;
};


&dsi_truly_1080_vid {
	qcom,panel-supply-entries = <&dsi_panel_pwr_supply>;
	qcom,mdss-dsi-pan-enable-dynamic-fps;
	qcom,mdss-dsi-min-refresh-rate = <48>;
	qcom,mdss-dsi-max-refresh-rate = <60>;
	qcom,mdss-dsi-pan-fps-update = "dfps_immediate_porch_mode_vfp";
};

&dsi_hx8399c_truly_vid {
	qcom,panel-supply-entries = <&dsi_panel_pwr_supply>;
	qcom,mdss-dsi-pan-enable-dynamic-fps;
	qcom,mdss-dsi-pan-fps-update = "dfps_immediate_porch_mode_vfp";
};

&dsi_truly_1080_cmd {
	qcom,panel-supply-entries = <&dsi_panel_pwr_supply>;
	qcom,ulps-enabled;
	qcom,partial-update-enabled;
	qcom,panel-roi-alignment = <2 2 4 2 1080 2>;
};

&soc {
//shiguohua_rh porting from WT patch 2019/3/19
	sn_fuse: snfuse@0xa0128 {
		compatible = "qcom,sn-fuse";
		reg = <0xa0128 0x4>;
		reg-names = "sn-base";
	};

	sec_boot_fuse: secbootfuse@0xa41d0 {
		compatible = "qcom,sec-boot-fuse";
		reg = <0xa41d0 0x4>;
		reg-names = "sec-boot-base";
	};





	gpio_keys {
		compatible = "gpio-keys";
		input-name = "gpio-keys";
		pinctrl-names = "default";
		pinctrl-0 = <&gpio_key_active>;

		camera_focus {
			label = "camera_focus";
			gpios = <&tlmm 87 0x1>;
			linux,input-type = <1>;
			linux,code = <0x210>;
			debounce-interval = <15>;
			linux,can-disable;
			gpio-key,wakeup;
		};

		camera_snapshot {
			label = "camera_snapshot";
			gpios = <&tlmm 86 0x1>;
			linux,input-type = <1>;
			linux,code = <0x2fe>;
			debounce-interval = <15>;
			linux,can-disable;
			gpio-key,wakeup;
		};
		vol_up {
			label = "volume_down";
			gpios = <&tlmm 85 0x1>;
			linux,input-type = <1>;
			linux,code = <114>;
			debounce-interval = <15>;
			linux,can-disable;
			gpio-key,wakeup;
		};
	};

	int_codec: sound {
		status = "okay";
		qcom,msm-mbhc-hphl-swh = <1>;
		qcom,msm-micbias2-ext-cap;
		qcom,audio-routing =
				"RX_BIAS", "MCLK",
				"SPK_RX_BIAS", "MCLK",
				"INT_LDO_H", "MCLK",
				"RX_I2S_CLK", "MCLK",
				"TX_I2S_CLK", "MCLK",
				"MIC BIAS External", "Handset Mic",
				"MIC BIAS Internal2", "Headset Mic",
				"AMIC1", "MIC BIAS External",
				"AMIC2", "MIC BIAS Internal2",
				"ADC1_IN", "ADC1_OUT",
				"ADC2_IN", "ADC2_OUT",
				"ADC3_IN", "ADC3_OUT",
				"PDM_IN_RX1", "PDM_OUT_RX1",
				"PDM_IN_RX2", "PDM_OUT_RX2",
				"PDM_IN_RX3", "PDM_OUT_RX3";

		qcom,msm-spk-ext-pa = <&tlmm 96 0>;
		qcom,cdc-us-euro-gpios;
		qcom,cdc-us-eu-gpios;
		asoc-wsa-codec-names;
	};

	i2c@78b6000 {
		status = "disabled";
		wsa881x_i2c_f: wsa881x-i2c-codec@f {
			status = "disabled";
		};
		wsa881x_i2c_45: wsa881x-i2c-codec@45 {
			status = "disabled";
		};
	};

};

&spmi_bus {
       qcom,pm8953@0 {
               qcom,power-on@800 {
                       qcom,pon_2 {
                               qcom,pon-type = <1>;
                               qcom,pull-up = <1>;
                               linux,code = <115>;
                       };
               };
       };
};

&thermal_zones {
	case-therm-step {
		status = "disabled";
	};

	quiet-therm-step {
		status = "disabled";
	};
};
